VERSION ""

NS_ :

BS_:

BU_: ADAS CDM EBA EBAM HDMap HNS HUD VDC

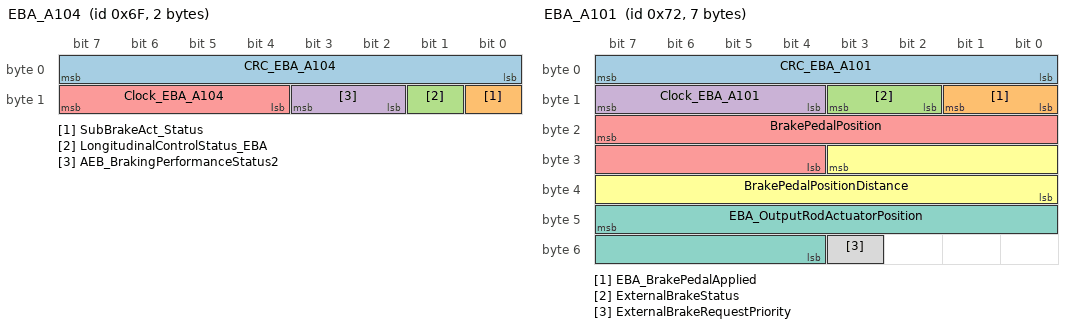
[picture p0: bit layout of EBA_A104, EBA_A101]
BO_ 111 EBA_A104: 2 EBA
  SG_ CRC_EBA_A104 : 7|8@0+ (1,0) [0|255] "" ADAS
  SG_ SubBrakeAct_Status : 8|1@0+ (1,0) [0|0] "" ADAS
  SG_ LongitudinalControlStatus_EBA : 9|1@0+ (1,0) [0|0] "" ADAS
  SG_ AEB_BrakingPerformanceStatus2 : 11|2@0+ (1,0) [0|0] "" ADAS
  SG_ Clock_EBA_A104 : 15|4@0+ (1,0) [0|15] "" ADAS

BO_ 114 EBA_A101: 7 EBA
  SG_ CRC_EBA_A101 : 7|8@0+ (1,0) [0|255] "" VDC
  SG_ EBA_BrakePedalApplied : 9|2@0+ (1,0) [0|0] "" VDC
  SG_ ExternalBrakeStatus : 11|2@0+ (1,0) [0|0] "" VDC
  SG_ Clock_EBA_A101 : 15|4@0+ (1,0) [0|15] "" VDC
  SG_ BrakePedalPosition : 23|12@0+ (0.03125,0) [0|100] "%" CDM
  SG_ BrakePedalPositionDistance : 27|12@0+ (0.015625,-5) [-5|47] "mm" CDM,VDC
  SG_ EBA_OutputRodActuatorPosition : 47|12@0+ (0.015625,-5) [-5|47] "mm" VDC
  SG_ ExternalBrakeRequestPriority : 51|1@0+ (1,0) [0|0] "" CDM,VDC

BO_ 116 ECM_A110: 8 CDM
  SG_ StopAutoPhase : 47|3@0+ (1,0) [0|0] "" HNS

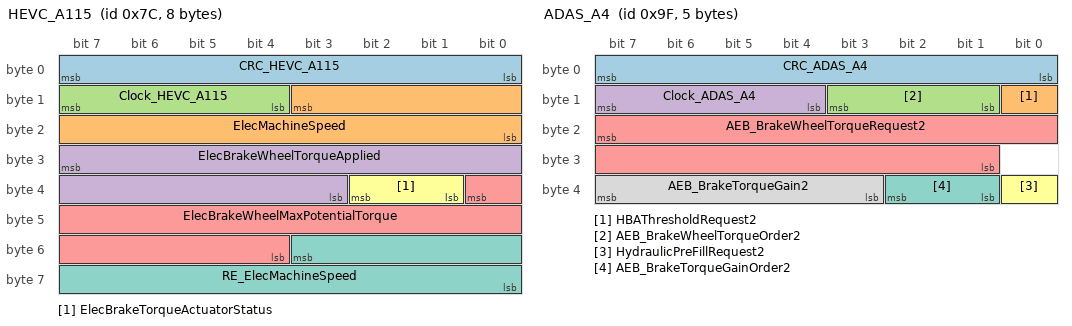
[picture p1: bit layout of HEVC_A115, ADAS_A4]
BO_ 124 HEVC_A115: 8 CDM
  SG_ CRC_HEVC_A115 : 7|8@0+ (1,0) [0|255] "" EBAM,VDC
  SG_ ElecMachineSpeed : 11|12@0+ (10,-20000) [-20000|20000] "rpm" EBAM,VDC
  SG_ Clock_HEVC_A115 : 15|4@0+ (1,0) [0|15] "" EBAM,VDC
  SG_ ElecBrakeWheelTorqueApplied : 31|13@0+ (1,0) [0|8190] "Nm" EBAM,VDC
  SG_ ElecBrakeWheelMaxPotentialTorque : 32|13@0+ (1,0) [0|8190] "Nm" EBAM,VDC
  SG_ ElecBrakeTorqueActuatorStatus : 34|2@0+ (1,0) [0|0] "" EBAM,VDC
  SG_ RE_ElecMachineSpeed : 51|12@0+ (10,-16390) [-16390|16390] "rpm" VDC

BO_ 159 ADAS_A4: 5 CDM
  SG_ CRC_ADAS_A4 : 7|8@0+ (1,0) [0|255] "" EBAM,VDC
  SG_ HBAThresholdRequest2 : 8|1@0+ (1,0) [0|0] "" EBAM,VDC
  SG_ AEB_BrakeWheelTorqueOrder2 : 11|3@0+ (1,0) [0|0] "" EBAM,VDC
  SG_ Clock_ADAS_A4 : 15|4@0+ (1,0) [0|15] "" EBAM,VDC
  SG_ AEB_BrakeWheelTorqueRequest2 : 23|15@0+ (1,0) [0|20000] "Nm" EBAM,VDC
  SG_ HydraulicPreFillRequest2 : 32|1@0+ (1,0) [0|0] "" EBAM,VDC
  SG_ AEB_BrakeTorqueGainOrder2 : 34|2@0+ (1,0) [0|0] "" EBAM,VDC
  SG_ AEB_BrakeTorqueGain2 : 39|5@0+ (0.05,1) [1|2] "" EBAM,VDC

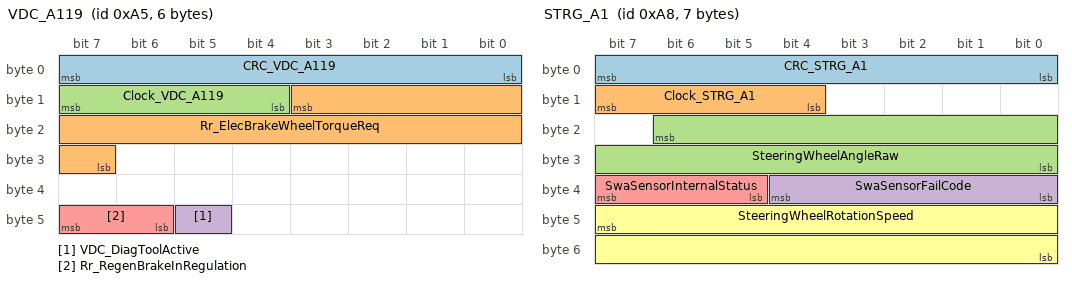
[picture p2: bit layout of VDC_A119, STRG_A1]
BO_ 165 VDC_A119: 6 VDC
  SG_ CRC_VDC_A119 : 7|8@0+ (1,0) [0|255] "" CDM,EBA
  SG_ Rr_ElecBrakeWheelTorqueReq : 11|13@0+ (1,0) [0|8190] "Nm" CDM
  SG_ Clock_VDC_A119 : 15|4@0+ (1,0) [0|15] "" CDM,EBA
  SG_ VDC_DiagToolActive : 45|1@0+ (1,0) [0|0] "" EBA
  SG_ Rr_RegenBrakeInRegulation : 47|2@0+ (1,0) [0|0] "" CDM

BO_ 168 STRG_A1: 7 CDM
  SG_ CRC_STRG_A1 : 7|8@0+ (1,0) [0|255] "" EBAM,VDC
  SG_ Clock_STRG_A1 : 15|4@0+ (1,0) [0|15] "" EBAM,VDC
  SG_ SteeringWheelAngleRaw : 22|15@0+ (0.1,-1080) [-1080|1080] "°" EBAM,VDC
  SG_ SwaSensorFailCode : 36|5@0+ (1,1) [1|31] "" EBAM,VDC
  SG_ SwaSensorInternalStatus : 39|3@0+ (1,0) [0|0] "" EBAM,VDC
  SG_ SteeringWheelRotationSpeed : 47|16@0+ (0.1,-3276.7) [-3276.7|3276.7] "°/s" EBAM,VDC

BO_ 336 AVM_A122: 7 CDM
  SG_ CRC_AVM_A122 : 7|8@0+ (1,0) [0|255] "" HNS,HUD
  SG_ Clock_AVM_A122 : 15|4@0+ (1,0) [0|15] "" HNS,HUD
  SG_ SubAD_ADmodeStatus : 52|3@0+ (1,0) [0|0] "" HNS,HUD

BO_ 354 VDC_A131: 5 VDC
  SG_ CRC_VDC_A131 : 7|8@0+ (1,0) [0|255] "" EBA
  SG_ Clock_VDC_A131 : 15|4@0+ (1,0) [0|15] "" EBA
  SG_ PathChangeRequest2 : 36|1@0+ (1,0) [0|0] "" EBA

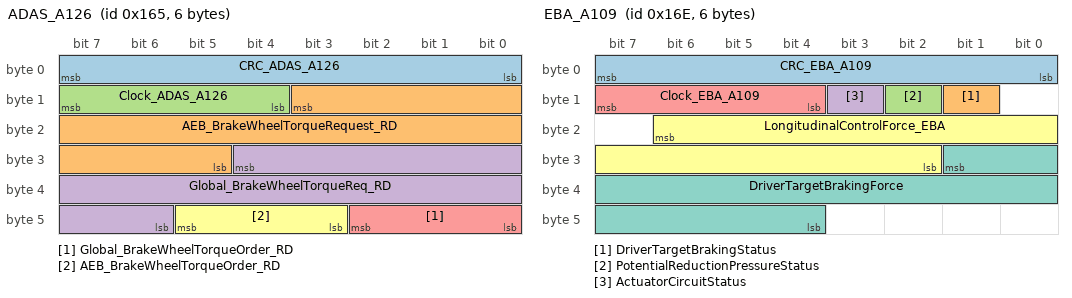
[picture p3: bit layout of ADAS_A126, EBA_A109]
BO_ 357 ADAS_A126: 6 ADAS
  SG_ CRC_ADAS_A126 : 7|8@0+ (1,0) [0|255] "" CDM,EBA
  SG_ AEB_BrakeWheelTorqueRequest_RD : 11|15@0+ (1,0) [0|20000] "Nm" EBA
  SG_ Clock_ADAS_A126 : 15|4@0+ (1,0) [0|15] "" CDM,EBA
  SG_ Global_BrakeWheelTorqueReq_RD : 28|15@0+ (1,0) [0|20000] "Nm" CDM,EBA
  SG_ Global_BrakeWheelTorqueOrder_RD : 42|3@0+ (1,0) [0|0] "" CDM,EBA
  SG_ AEB_BrakeWheelTorqueOrder_RD : 45|3@0+ (1,0) [0|0] "" EBA

BO_ 366 EBA_A109: 6 EBA
  SG_ CRC_EBA_A109 : 7|8@0+ (1,0) [0|255] "" VDC
  SG_ DriverTargetBrakingStatus : 9|1@0+ (1,0) [0|0] "" VDC
  SG_ PotentialReductionPressureStatus : 10|1@0+ (1,0) [0|0] "" VDC
  SG_ ActuatorCircuitStatus : 11|1@0+ (1,0) [0|0] "" VDC
  SG_ Clock_EBA_A109 : 15|4@0+ (1,0) [0|15] "" VDC
  SG_ LongitudinalControlForce_EBA : 22|13@0+ (8,0) [0|65000] "N" VDC
  SG_ DriverTargetBrakingForce : 25|14@0+ (8,0) [0|130000] "N" VDC

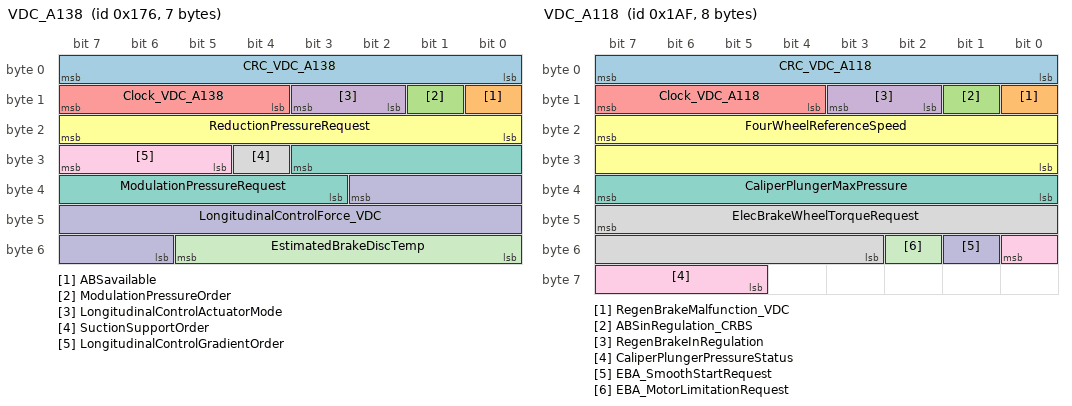
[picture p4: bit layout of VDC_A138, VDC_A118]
BO_ 374 VDC_A138: 7 VDC
  SG_ CRC_VDC_A138 : 7|8@0+ (1,0) [0|255] "" EBA
  SG_ ABSavailable : 8|1@0+ (1,0) [0|0] "" EBA
  SG_ ModulationPressureOrder : 9|1@0+ (1,0) [0|0] "" EBA
  SG_ LongitudinalControlActuatorMode : 11|2@0+ (1,0) [0|0] "" EBA
  SG_ Clock_VDC_A138 : 15|4@0+ (1,0) [0|15] "" EBA
  SG_ ReductionPressureRequest : 23|8@0+ (0.25,0) [0|60] "bar" EBA
  SG_ ModulationPressureRequest : 27|9@0+ (0.25,0) [0|120] "bar" EBA
  SG_ SuctionSupportOrder : 28|1@0+ (1,0) [0|0] "" EBA
  SG_ LongitudinalControlGradientOrder : 31|3@0+ (1,0) [0|0] "" EBA
  SG_ LongitudinalControlForce_VDC : 34|13@0+ (8,0) [0|65000] "N" EBA
  SG_ EstimatedBrakeDiscTemp : 53|6@0+ (15,0) [0|945] "?" EBA

BO_ 431 VDC_A118: 8 EBAM
  SG_ CRC_VDC_A118 : 7|8@0+ (1,0) [0|255] "" CDM,EBA
  SG_ RegenBrakeMalfunction_VDC : 8|1@0+ (1,0) [0|0] "" CDM
  SG_ ABSinRegulation_CRBS : 9|1@0+ (1,0) [0|0] "" EBA
  SG_ RegenBrakeInRegulation : 11|2@0+ (1,0) [0|0] "" CDM
  SG_ Clock_VDC_A118 : 15|4@0+ (1,0) [0|15] "" CDM,EBA
  SG_ FourWheelReferenceSpeed : 23|16@0+ (0.01,0) [0|655.34] "km/h" CDM,EBA
  SG_ CaliperPlungerMaxPressure : 39|8@0+ (0.1,0) [0|25] "MPa" EBA
  SG_ ElecBrakeWheelTorqueRequest : 47|13@0+ (1,0) [0|8190] "Nm" CDM
  SG_ CaliperPlungerPressureStatus : 48|4@0+ (1,0) [0|0] "" EBA
  SG_ EBA_SmoothStartRequest : 49|1@0+ (1,0) [0|0] "" EBA
  SG_ EBA_MotorLimitationRequest : 50|1@0+ (1,0) [0|0] "" EBA

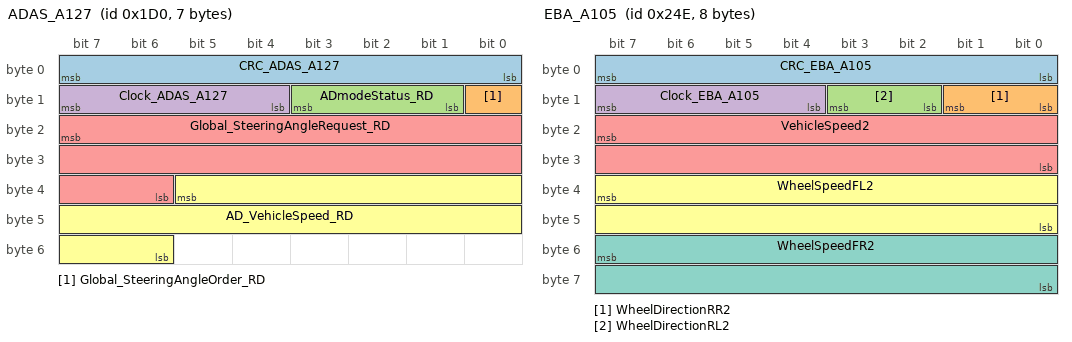
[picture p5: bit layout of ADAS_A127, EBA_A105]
BO_ 464 ADAS_A127: 7 ADAS
  SG_ CRC_ADAS_A127 : 7|8@0+ (1,0) [0|255] "" CDM,EBA,HNS,HUD,VDC
  SG_ Global_SteeringAngleOrder_RD : 8|1@0+ (1,0) [0|0] "" CDM
  SG_ ADmodeStatus_RD : 11|3@0+ (1,0) [0|0] "" EBA,HNS,HUD,VDC
  SG_ Clock_ADAS_A127 : 15|4@0+ (1,0) [0|15] "" CDM,EBA,HNS,HUD,VDC
  SG_ Global_SteeringAngleRequest_RD : 23|18@0+ (0.01,-1310) [-1310|1310] "deg" CDM
  SG_ AD_VehicleSpeed_RD : 37|16@0+ (0.01,0) [0|655.34] "km/h" EBA

BO_ 570 EBA_A108: 4 EBA
  SG_ CRC_EBA_A108 : 7|8@0+ (1,0) [0|255] "" ADAS
  SG_ VehicleSpeedBody2 : 11|16@0+ (0.01,0) [0|655.34] "km/h" ADAS
  SG_ Clock_EBA_A108 : 15|4@0+ (1,0) [0|15] "" ADAS

BO_ 590 EBA_A105: 8 EBA
  SG_ CRC_EBA_A105 : 7|8@0+ (1,0) [0|255] "" ADAS,CDM
  SG_ WheelDirectionRR2 : 9|2@0+ (1,0) [0|0] "" ADAS
  SG_ WheelDirectionRL2 : 11|2@0+ (1,0) [0|0] "" ADAS
  SG_ Clock_EBA_A105 : 15|4@0+ (1,0) [0|15] "" ADAS,CDM
  SG_ VehicleSpeed2 : 23|16@0+ (0.01,0) [0|655.34] "km/h" ADAS,CDM
  SG_ WheelSpeedFL2 : 39|16@0+ (0.0416666667,0) [0|2730.583333] "rpm" ADAS,CDM
  SG_ WheelSpeedFR2 : 55|16@0+ (0.0416666667,0) [0|2730.583333] "rpm" ADAS,CDM

BO_ 591 EBA_A106: 7 EBA
  SG_ CRC_EBA_A106 : 7|8@0+ (1,0) [0|255] "" ADAS,CDM
  SG_ Clock_EBA_A106 : 15|4@0+ (1,0) [0|15] "" ADAS,CDM
  SG_ WheelSpeedRL2 : 31|16@0+ (0.0416666667,0) [0|2730.583333] "rpm" ADAS,CDM
  SG_ WheelSpeedRR2 : 47|16@0+ (0.0416666667,0) [0|2730.583333] "rpm" ADAS,CDM

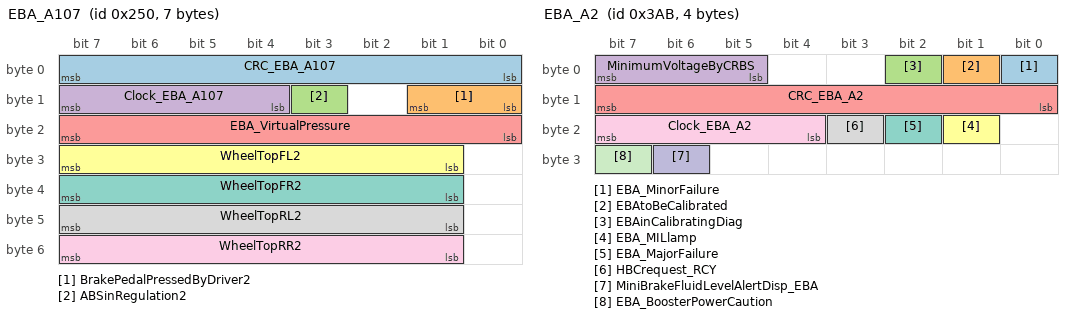
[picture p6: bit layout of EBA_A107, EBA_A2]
BO_ 592 EBA_A107: 7 EBA
  SG_ CRC_EBA_A107 : 7|8@0+ (1,0) [0|255] "" ADAS
  SG_ BrakePedalPressedByDriver2 : 9|2@0+ (1,0) [0|0] "" ADAS
  SG_ ABSinRegulation2 : 11|1@0+ (1,0) [0|0] "" ADAS
  SG_ Clock_EBA_A107 : 15|4@0+ (1,0) [0|15] "" ADAS
  SG_ EBA_VirtualPressure : 23|8@0+ (0.5,0) [0|126] "bar" ADAS
  SG_ WheelTopFL2 : 31|7@0+ (1,0) [0|96] "top" ADAS
  SG_ WheelTopFR2 : 39|7@0+ (1,0) [0|96] "top" ADAS
  SG_ WheelTopRL2 : 47|7@0+ (1,0) [0|96] "top" ADAS
  SG_ WheelTopRR2 : 55|7@0+ (1,0) [0|96] "top" ADAS

BO_ 650 VDC_A9: 8 VDC
  SG_ VehicleSpeed : 39|16@0+ (0.01,0) [0|655.34] "km/h" HDMap,HNS,HUD
  SG_ VehicleSpeedClock : 51|4@0+ (1,0) [0|15] "" HDMap
  SG_ VehicleSpeedCRC : 63|8@0+ (1,0) [0|255] "" HDMap

BO_ 732 EPKB_A102: 2 VDC
  SG_ CRC_EPKB_A102 : 7|8@0+ (1,0) [0|255] "" ADAS
  SG_ ParkingBrakeBindingStatus_RD : 11|2@0+ (1,0) [0|0] "" ADAS
  SG_ Clock_EPKB_A102 : 15|4@0+ (1,0) [0|15] "" ADAS

BO_ 747 EDL_A101: 2 CDM
  SG_ DiffLockOperatingFlag : 0|1@0+ (1,0) [0|0] "" EBAM,VDC
  SG_ DiffLockControllerFailure : 1|1@0+ (1,0) [0|0] "" EBAM,VDC
  SG_ DiffLockSwitching_EDL : 15|1@0+ (1,0) [0|0] "" VDC

BO_ 772 ADAS_A148: 4 ADAS
  SG_ AD_SteeringAngleDisplay : 31|8@0+ (1,0) [0|0] "" HUD

BO_ 806 USM_R3: 2 CDM
  SG_ FrontHeightBody : 7|8@0+ (1.5,-190.5) [-190.5|190.5] "mm" EBAM,VDC
  SG_ RearHeightBody : 15|8@0+ (1.5,-190.5) [-190.5|190.5] "mm" EBAM,VDC

BO_ 879 METER_A4: 4 CDM
  SG_ MemorizedDistanceTotalizer : 7|28@0+ (0.01,0) [0|2600000] "km" EBAM,VDC

BO_ 930 ADAS_A123: 6 CDM
  SG_ DMC_UnresponsiveAlertStatus : 37|3@0+ (1,0) [0|0] "" HUD

BO_ 939 EBA_A2: 4 EBA
  SG_ EBA_MinorFailure : 0|1@0+ (1,0) [0|0] "" CDM,VDC
  SG_ EBAtoBeCalibrated : 1|1@0+ (1,0) [0|0] "" CDM
  SG_ EBAinCalibratingDiag : 2|1@0+ (1,0) [0|0] "" CDM
  SG_ MinimumVoltageByCRBS : 7|3@0+ (0.5,12) [12|15] "V" CDM
  SG_ CRC_EBA_A2 : 15|8@0+ (1,0) [0|255] "" CDM,VDC
  SG_ EBA_MILlamp : 17|1@0+ (1,0) [0|0] "" CDM
  SG_ EBA_MajorFailure : 18|1@0+ (1,0) [0|0] "" CDM,VDC
  SG_ HBCrequest_RCY : 19|1@0+ (1,0) [0|0] "" VDC
  SG_ Clock_EBA_A2 : 23|4@0+ (1,0) [0|15] "" CDM,VDC
  SG_ MiniBrakeFluidLevelAlertDisp_EBA : 30|1@0+ (1,0) [0|0] "" VDC
  SG_ EBA_BoosterPowerCaution : 31|1@0+ (1,0) [0|0] "" CDM

BO_ 944 BCM_A117: 3 CDM
  SG_ CRC_BCM_A117 : 7|8@0+ (1,0) [0|255] "" EBA,EBAM,VDC
  SG_ Clock_BCM_A117 : 15|4@0+ (1,0) [0|15] "" EBA,EBAM,VDC
  SG_ RPES_Status : 23|3@0+ (1,0) [0|0] "" EBA,EBAM,VDC

BO_ 961 IVI_A112: 8 CDM
  SG_ DistanceBeforeNextAction : 7|40@0+ (1,0) [0|0] "" HUD
  SG_ UnitDistanceBeforeNextAction : 47|4@0+ (1,0) [0|0] "" HUD

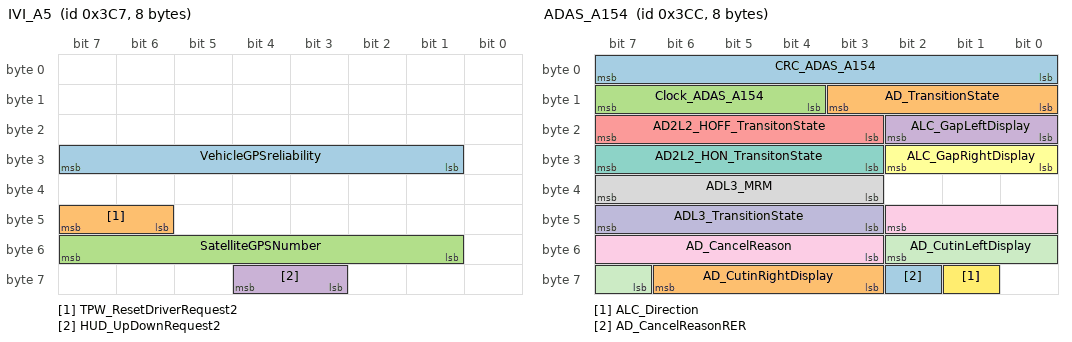
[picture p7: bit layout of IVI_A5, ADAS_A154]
BO_ 967 IVI_A5: 8 CDM
  SG_ VehicleGPSreliability : 31|7@0+ (1,0) [0|127] "" VDC
  SG_ TPW_ResetDriverRequest2 : 47|2@0+ (1,0) [0|0] "" EBAM,VDC
  SG_ SatelliteGPSNumber : 55|7@0+ (1,0) [0|126] "wu" VDC
  SG_ HUD_UpDownRequest2 : 60|2@0+ (1,0) [0|0] "" HUD

BO_ 972 ADAS_A154: 8 ADAS
  SG_ CRC_ADAS_A154 : 7|8@0+ (1,0) [0|255] "" HUD
  SG_ AD_TransitionState : 11|4@0+ (1,0) [0|0] "" HUD
  SG_ Clock_ADAS_A154 : 15|4@0+ (1,0) [0|15] "" HUD
  SG_ ALC_GapLeftDisplay : 18|3@0+ (1,0) [0|0] "" HUD
  SG_ AD2L2_HOFF_TransitonState : 23|5@0+ (1,0) [0|0] "" HUD
  SG_ ALC_GapRightDisplay : 26|3@0+ (1,0) [0|0] "" HUD
  SG_ AD2L2_HON_TransitonState : 31|5@0+ (1,0) [0|0] "" HUD
  SG_ ADL3_MRM : 39|5@0+ (1,0) [0|0] "" HUD
  SG_ AD_CancelReason : 42|8@0+ (1,0) [0|255] "CancelReason" HUD
  SG_ ADL3_TransitionState : 47|5@0+ (1,0) [0|0] "" HUD
  SG_ AD_CutinLeftDisplay : 50|4@0+ (1,0) [0|0] "" HUD
  SG_ ALC_Direction : 57|1@0+ (1,0) [0|0] "" HUD
  SG_ AD_CancelReasonRER : 58|1@0+ (1,0) [0|0] "" HUD
  SG_ AD_CutinRightDisplay : 62|4@0+ (1,0) [0|0] "" HUD

BO_ 974 ADAS_A147: 7 ADAS
  SG_ CRC_ADAS_A147 : 7|8@0+ (1,0) [0|255] "" VDC
  SG_ ParkingBrakeBindingRequest_RD : 11|1@0+ (1,0) [0|0] "" VDC
  SG_ Clock_ADAS_A147 : 15|4@0+ (1,0) [0|15] "" VDC

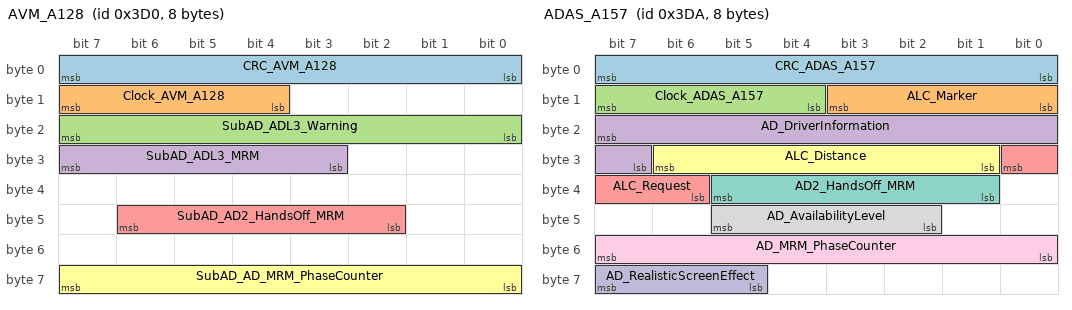
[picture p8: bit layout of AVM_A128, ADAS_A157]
BO_ 976 AVM_A128: 8 CDM
  SG_ CRC_AVM_A128 : 7|8@0+ (1,0) [0|255] "" HUD
  SG_ Clock_AVM_A128 : 15|4@0+ (1,0) [0|15] "" HUD
  SG_ SubAD_ADL3_Warning : 23|8@0+ (1,0) [0|255] "Warning" HUD
  SG_ SubAD_ADL3_MRM : 31|5@0+ (1,0) [0|0] "" HUD
  SG_ SubAD_AD2_HandsOff_MRM : 46|5@0+ (1,0) [0|0] "" HUD
  SG_ SubAD_AD_MRM_PhaseCounter : 63|8@0+ (0.2,-0.2) [0|50.6] "s" HUD

BO_ 977 CDM_A127: 3 CDM
  SG_ CRC_CDM_A127 : 7|8@0+ (1,0) [0|255] "" HNS
  SG_ HNS_Opening_Request : 8|1@0+ (1,0) [0|0] "" HNS
  SG_ HNS_Diagnostic_Req : 9|1@0+ (1,0) [0|0] "" HNS
  SG_ Clock_CDM_A127 : 15|4@0+ (1,0) [0|15] "" HNS

BO_ 986 ADAS_A157: 8 ADAS
  SG_ CRC_ADAS_A157 : 7|8@0+ (1,0) [0|255] "" HUD
  SG_ ALC_Marker : 11|4@0+ (1,0) [0|0] "" HUD
  SG_ Clock_ADAS_A157 : 15|4@0+ (1,0) [0|15] "" HUD
  SG_ AD_DriverInformation : 23|9@0+ (1,0) [0|511] "Instruction" HUD
  SG_ ALC_Request : 24|3@0+ (1,0) [0|0] "" HUD
  SG_ ALC_Distance : 30|6@0+ (100,-100) [0|6000] "m" HUD
  SG_ AD2_HandsOff_MRM : 37|5@0+ (1,0) [0|0] "" HUD
  SG_ AD_AvailabilityLevel : 45|4@0+ (1,0) [0|0] "" HUD
  SG_ AD_MRM_PhaseCounter : 55|8@0+ (0.2,-0.2) [0|50.6] "s" HUD
  SG_ AD_RealisticScreenEffect : 63|3@0+ (1,0) [0|0] "" HUD

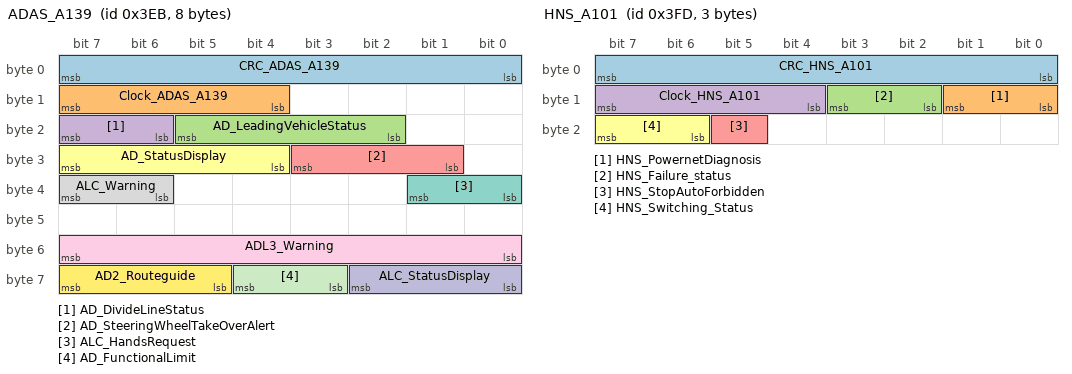
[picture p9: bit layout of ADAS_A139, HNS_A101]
BO_ 1003 ADAS_A139: 8 ADAS
  SG_ CRC_ADAS_A139 : 7|8@0+ (1,0) [0|255] "" HUD
  SG_ Clock_ADAS_A139 : 15|4@0+ (1,0) [0|15] "" HUD
  SG_ AD_LeadingVehicleStatus : 21|4@0+ (1,0) [0|0] "" HUD
  SG_ AD_DivideLineStatus : 23|2@0+ (1,0) [0|0] "" HUD
  SG_ AD_SteeringWheelTakeOverAlert : 27|3@0+ (1,0) [0|0] "" HUD
  SG_ AD_StatusDisplay : 31|4@0+ (1,0) [0|0] "" HUD
  SG_ ALC_HandsRequest : 33|2@0+ (1,0) [0|0] "" HUD
  SG_ ALC_Warning : 39|2@0+ (1,0) [0|0] "" HUD
  SG_ ADL3_Warning : 55|8@0+ (1,0) [0|255] "Warning" HUD
  SG_ ALC_StatusDisplay : 58|3@0+ (1,0) [0|0] "" HUD
  SG_ AD_FunctionalLimit : 60|2@0+ (1,0) [0|0] "" HUD
  SG_ AD2_Routeguide : 63|3@0+ (1,0) [0|0] "" HUD

BO_ 1021 HNS_A101: 3 HNS
  SG_ CRC_HNS_A101 : 7|8@0+ (1,0) [0|255] "" CDM
  SG_ HNS_PowernetDiagnosis : 9|2@0+ (1,0) [0|0] "" CDM
  SG_ HNS_Failure_status : 11|2@0+ (1,0) [0|0] "" CDM
  SG_ Clock_HNS_A101 : 15|4@0+ (1,0) [0|15] "" CDM
  SG_ HNS_StopAutoForbidden : 21|1@0+ (1,0) [0|0] "" CDM
  SG_ HNS_Switching_Status : 23|2@0+ (1,0) [0|0] "" CDM

BO_ 1058 FRCAMERA_A111: 5 CDM
  SG_ TSR_ConfidenceLevel : 39|3@0+ (20,0) [0|100] "%" HUD

BO_ 1068 HEVC_A108: 8 CDM
  SG_ AnticipatedElectricGearChange : 0|1@0+ (1,0) [0|0] "" VDC
  SG_ VehicleTractionMode : 15|3@0+ (1,0) [0|0] "" EBAM,VDC

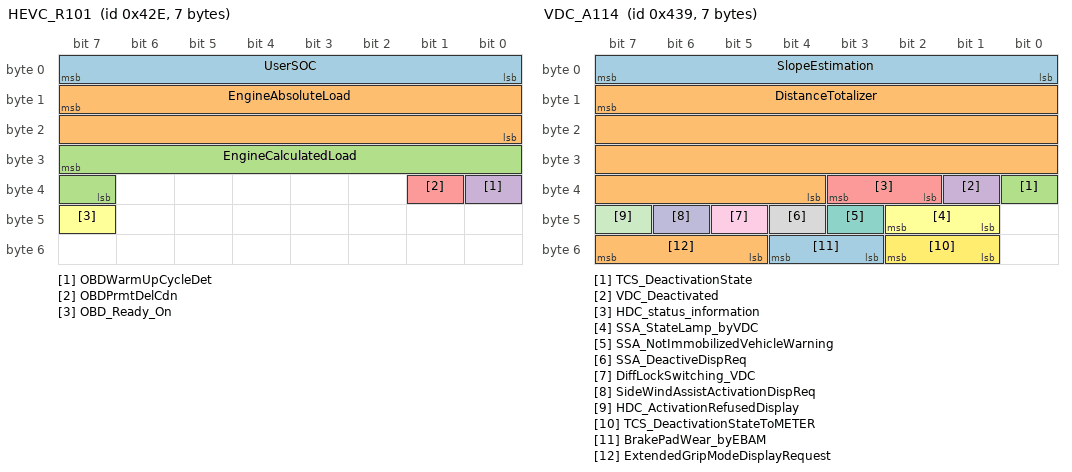
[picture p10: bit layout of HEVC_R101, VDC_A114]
BO_ 1070 HEVC_R101: 7 CDM
  SG_ UserSOC : 7|8@0+ (0.392157,0) [0|100] "%" EBA,EBAM
  SG_ EngineAbsoluteLoad : 15|16@0+ (0.39,0) [0|25700] "%" EBA
  SG_ EngineCalculatedLoad : 31|9@0+ (0.39,0) [0|100] "%" EBA,EBAM,VDC
  SG_ OBDWarmUpCycleDet : 32|1@0+ (1,0) [0|0] "" EBA,EBAM,VDC
  SG_ OBDPrmtDelCdn : 33|1@0+ (1,0) [0|0] "" EBA,EBAM,VDC
  SG_ OBD_Ready_On : 47|1@0+ (1,0) [0|0] "" EBA,EBAM,VDC

BO_ 1081 VDC_A114: 7 EBAM
  SG_ SlopeEstimation : 7|8@0+ (0.2,-15) [-15|15] "°" CDM
  SG_ DistanceTotalizer : 15|28@0+ (0.01,0) [0|2600000] "km" CDM,EBA,HNS,HUD
  SG_ TCS_DeactivationState : 32|1@0+ (1,0) [0|0] "" CDM
  SG_ VDC_Deactivated : 33|1@0+ (1,0) [0|0] "" CDM
  SG_ HDC_status_information : 35|2@0+ (1,0) [0|0] "" CDM
  SG_ SSA_StateLamp_byVDC : 42|2@0+ (1,0) [0|0] "" CDM
  SG_ SSA_NotImmobilizedVehicleWarning : 43|1@0+ (1,0) [0|0] "" CDM
  SG_ SSA_DeactiveDispReq : 44|1@0+ (1,0) [0|0] "" CDM
  SG_ DiffLockSwitching_VDC : 45|1@0+ (1,0) [0|0] "" CDM
  SG_ SideWindAssistActivationDispReq : 46|1@0+ (1,0) [0|0] "" CDM
  SG_ HDC_ActivationRefusedDisplay : 47|1@0+ (1,0) [0|0] "" CDM
  SG_ TCS_DeactivationStateToMETER : 50|2@0+ (1,0) [0|0] "" CDM
  SG_ BrakePadWear_byEBAM : 52|2@0+ (1,0) [0|0] "" CDM
  SG_ ExtendedGripModeDisplayRequest : 55|3@0+ (1,0) [0|0] "" CDM

BO_ 1099 ATCU_A109: 8 CDM
  SG_ AT_GearShiftRefused : 31|1@0+ (1,0) [0|0] "" HUD
  SG_ ATCVT_RangeIndicationExtended : 44|6@0+ (1,0) [0|0] "" HUD

BO_ 1101 BCM_A107: 5 ADAS
  SG_ FlashingIndicatorStatusDisplay : 23|3@0+ (1,0) [0|0] "" HUD

BO_ 1104 METER_A103: 8 CDM
  SG_ RawFuelGaugeResistance : 7|10@0+ (1,0) [0|1022] "Ohm" EBA

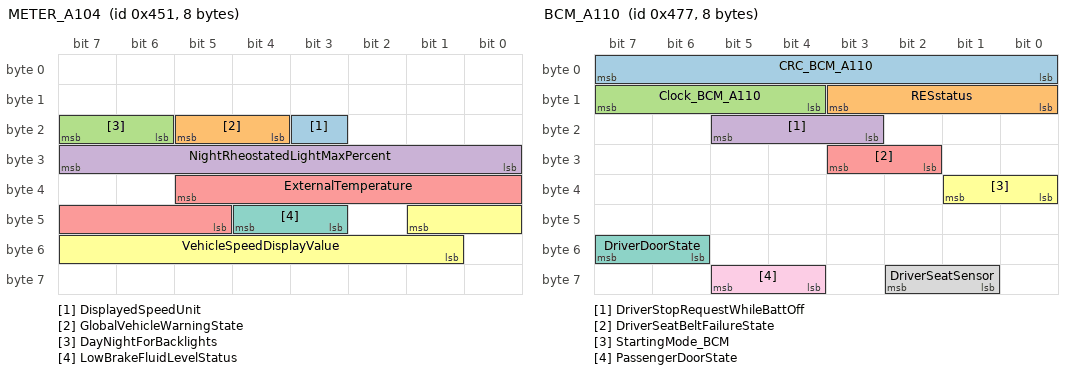
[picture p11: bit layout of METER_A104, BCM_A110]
BO_ 1105 METER_A104: 8 CDM
  SG_ DisplayedSpeedUnit : 19|1@0+ (1,0) [0|0] "" HUD
  SG_ GlobalVehicleWarningState : 21|2@0+ (1,0) [0|0] "" HUD
  SG_ DayNightForBacklights : 23|2@0+ (1,0) [0|0] "" HUD
  SG_ NightRheostatedLightMaxPercent : 31|8@0+ (0.4,0) [0|100] "%" HUD
  SG_ ExternalTemperature : 37|9@0+ (0.25,-50) [-50|70] "°C" HUD
  SG_ VehicleSpeedDisplayValue : 41|9@0+ (1,0) [0|510] "" HUD
  SG_ LowBrakeFluidLevelStatus : 44|2@0+ (1,0) [0|0] "" EBA

BO_ 1107 USM_A101: 8 CDM
  SG_ CRC_USM_A101 : 7|8@0+ (1,0) [0|255] "" EBA
  SG_ Clock_USM_A101 : 15|4@0+ (1,0) [0|15] "" EBA
  SG_ IgnitionSupplyConfirmation : 20|1@0+ (1,0) [0|0] "" EBA,HUD
  SG_ BatteryVoltage : 31|8@0+ (0.06,6) [6|18] "V" EBA,HNS,HUD

BO_ 1108 USM_A103: 8 CDM
  SG_ SOCBattery14V : 13|6@0+ (0.5,69) [69|100] "%" HNS
  SG_ Storage12V_SwitchRequest : 53|1@0+ (1,0) [0|0] "" HNS

BO_ 1110 BMS12V_A101: 8 CDM
  SG_ BMS12V_StorageSOC : 37|10@0+ (0.1,0) [0|100] "%" HNS
  SG_ BMS12V_SwitchState : 41|1@0+ (1,0) [0|0] "" HNS
  SG_ BMS12V_StorageFailure : 43|2@0+ (1,0) [0|0] "" HNS

BO_ 1116 CDM_A116: 8 CDM
  SG_ SSA_StateLamp : 3|2@0+ (1,0) [0|0] "" HUD

BO_ 1119 ECM_A108: 4 CDM
  SG_ EngineCoolantTemp : 23|8@0+ (1,-40) [-40|214] "°C" EBA

BO_ 1137 ECM_A114: 8 CDM
  SG_ RequestedSpeedDisplayRequest : 15|8@0+ (1,0) [0|253] "" HUD
  SG_ Maintenance_Mode_Status : 25|2@0+ (1,0) [0|0] "" EBA,EBAM,VDC
  SG_ CruiseControlStatus : 31|3@0+ (1,0) [0|0] "" EBAM,HUD,VDC

BO_ 1138 ECM_A116: 8 CDM
  SG_ OverspeedIndicationDisplayReq : 25|1@0+ (1,0) [0|0] "" HUD
  SG_ OverSpeedAlert_SL : 47|1@0+ (1,0) [0|0] "" HUD

BO_ 1139 ECM_A117: 6 CDM
  SG_ AtmoPressure : 7|10@0+ (0.1,10) [10|110] "kPa" VDC
  SG_ Rr_TransmRangeEngaged_Current : 26|2@0+ (1,0) [0|0] "" VDC
  SG_ AcceleratorPedalPositionD : 39|8@0+ (0.39215686274509803,0) [0|100] "%" EBA,EBAM,VDC
  SG_ Rr_TransmRangeEngaged_Target : 47|2@0+ (1,0) [0|0] "" VDC

BO_ 1140 ADAS_A116: 8 CDM
  SG_ LKA_AlertStatus : 9|2@0+ (1,0) [0|0] "" HUD
  SG_ LKA_SWheelTakeOverAlert_v3 : 23|3@0+ (1,0) [0|0] "" HUD

BO_ 1143 BCM_A110: 8 CDM
  SG_ CRC_BCM_A110 : 7|8@0+ (1,0) [0|255] "" EBAM,VDC
  SG_ RESstatus : 11|4@0+ (1,0) [0|0] "" HUD
  SG_ Clock_BCM_A110 : 15|4@0+ (1,0) [0|15] "" EBAM,VDC
  SG_ DriverStopRequestWhileBattOff : 21|3@0+ (1,0) [0|0] "" EBAM,VDC
  SG_ DriverSeatBeltFailureState : 27|2@0+ (1,0) [0|0] "" EBAM,VDC
  SG_ StartingMode_BCM : 33|2@0+ (1,0) [0|0] "" EBAM,VDC
  SG_ DriverDoorState : 55|2@0+ (1,0) [0|0] "" EBAM,VDC
  SG_ DriverSeatSensor : 58|2@0+ (1,0) [0|0] "" EBAM
  SG_ PassengerDoorState : 61|2@0+ (1,0) [0|0] "" EBAM,VDC

BO_ 1145 BCM_A112: 8 CDM
  SG_ ProbableCustomerFeedBackNeed : 41|1@0+ (1,0) [0|0] "" EBAM,VDC
  SG_ AutoACC2Status_MM : 55|2@0+ (1,0) [0|0] "" HUD

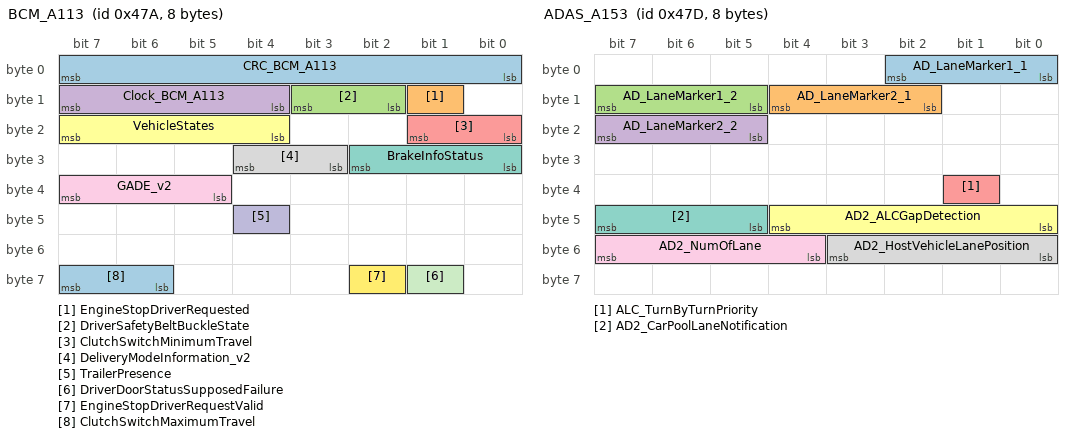
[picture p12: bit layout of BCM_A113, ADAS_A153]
BO_ 1146 BCM_A113: 8 CDM
  SG_ CRC_BCM_A113 : 7|8@0+ (1,0) [0|255] "" EBAM,VDC
  SG_ EngineStopDriverRequested : 9|1@0+ (1,0) [0|0] "" EBAM,VDC
  SG_ DriverSafetyBeltBuckleState : 11|2@0+ (1,0) [0|0] "" EBAM,VDC
  SG_ Clock_BCM_A113 : 15|4@0+ (1,0) [0|15] "" EBAM,VDC
  SG_ ClutchSwitchMinimumTravel : 17|2@0+ (1,0) [0|0] "" EBAM,VDC
  SG_ VehicleStates : 23|4@0+ (1,0) [0|0] "" EBAM,HDMap,HNS,HUD,VDC
  SG_ BrakeInfoStatus : 26|3@0+ (1,0) [0|0] "" EBAM,VDC
  SG_ DeliveryModeInformation_v2 : 28|2@0+ (1,0) [0|0] "" EBAM,HUD,VDC
  SG_ GADE_v2 : 39|3@0+ (1,0) [0|0] "" EBAM,HNS,HUD,VDC
  SG_ TrailerPresence : 44|1@0+ (1,0) [0|0] "" EBAM,VDC
  SG_ DriverDoorStatusSupposedFailure : 57|1@0+ (1,0) [0|0] "" EBAM,VDC
  SG_ EngineStopDriverRequestValid : 58|1@0+ (1,0) [0|0] "" EBAM,VDC
  SG_ ClutchSwitchMaximumTravel : 63|2@0+ (1,0) [0|0] "" EBAM,VDC

BO_ 1149 ADAS_A153: 8 ADAS
  SG_ AD_LaneMarker1_1 : 2|3@0+ (1,0) [0|0] "" HUD
  SG_ AD_LaneMarker2_1 : 12|3@0+ (1,0) [0|0] "" HUD
  SG_ AD_LaneMarker1_2 : 15|3@0+ (1,0) [0|0] "" HUD
  SG_ AD_LaneMarker2_2 : 23|3@0+ (1,0) [0|0] "" HUD
  SG_ ALC_TurnByTurnPriority : 33|1@0+ (1,0) [0|0] "" HUD
  SG_ AD2_ALCGapDetection : 44|5@0+ (1,0) [0|0] "" HUD
  SG_ AD2_CarPoolLaneNotification : 47|3@0+ (1,0) [0|0] "" HUD
  SG_ AD2_HostVehicleLanePosition : 51|4@0+ (1,0) [0|0] "" HUD
  SG_ AD2_NumOfLane : 55|4@0+ (1,0) [0|0] "" HUD

BO_ 1176 ADAS_N104: 8 CDM
  SG_ RMF_StatusDisplay : 51|3@0+ (1,0) [0|0] "" HUD
  SG_ RMF_StateDisplayRequest : 55|4@0+ (1,0) [0|0] "" HUD
  SG_ RMF_FailureDisplay : 63|3@0+ (1,0) [0|0] "" HUD

BO_ 1189 BCM_N101: 8 CDM
  SG_ UserIdentification_IKeyLink_v2 : 39|4@0+ (1,0) [0|0] "" HUD

BO_ 1203 FRCAMERA_A110: 5 CDM
  SG_ OSPSpeedLimit_Display : 7|8@0+ (1,5) [5|200] "Kmh/Mph" HUD

BO_ 1278 FrCamADAS_R101: 5 CDM
  SG_ LCA_WarningStatus : 26|3@0+ (1,0) [0|0] "" HUD

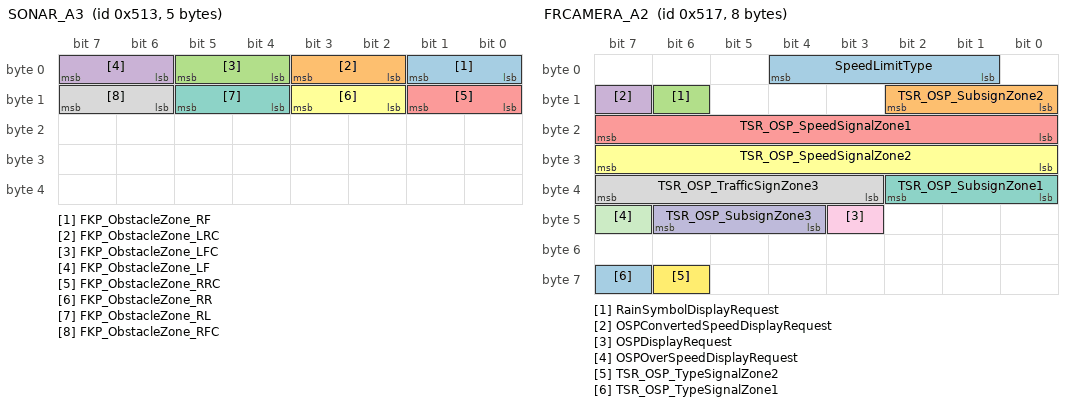
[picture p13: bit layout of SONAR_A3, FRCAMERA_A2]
BO_ 1299 SONAR_A3: 5 CDM
  SG_ FKP_ObstacleZone_RF : 1|2@0+ (1,0) [0|0] "" HUD
  SG_ FKP_ObstacleZone_LRC : 3|2@0+ (1,0) [0|0] "" HUD
  SG_ FKP_ObstacleZone_LFC : 5|2@0+ (1,0) [0|0] "" HUD
  SG_ FKP_ObstacleZone_LF : 7|2@0+ (1,0) [0|0] "" HUD
  SG_ FKP_ObstacleZone_RRC : 9|2@0+ (1,0) [0|0] "" HUD
  SG_ FKP_ObstacleZone_RR : 11|2@0+ (1,0) [0|0] "" HUD
  SG_ FKP_ObstacleZone_RL : 13|2@0+ (1,0) [0|0] "" HUD
  SG_ FKP_ObstacleZone_RFC : 15|2@0+ (1,0) [0|0] "" HUD

BO_ 1303 FRCAMERA_A2: 8 CDM
  SG_ SpeedLimitType : 4|4@0+ (1,0) [0|0] "" HUD
  SG_ TSR_OSP_SubsignZone2 : 10|3@0+ (1,0) [0|0] "" HUD
  SG_ RainSymbolDisplayRequest : 14|1@0+ (1,0) [0|0] "" HUD
  SG_ OSPConvertedSpeedDisplayRequest : 15|1@0+ (1,0) [0|0] "" HUD
  SG_ TSR_OSP_SpeedSignalZone1 : 23|8@0+ (1,0) [0|200] "wu" HUD
  SG_ TSR_OSP_SpeedSignalZone2 : 31|8@0+ (1,0) [0|200] "wu" HUD
  SG_ TSR_OSP_SubsignZone1 : 34|3@0+ (1,0) [0|0] "" HUD
  SG_ TSR_OSP_TrafficSignZone3 : 39|5@0+ (1,0) [0|0] "" HUD
  SG_ OSPDisplayRequest : 43|1@0+ (1,0) [0|0] "" HUD
  SG_ TSR_OSP_SubsignZone3 : 46|3@0+ (1,0) [0|0] "" HUD
  SG_ OSPOverSpeedDisplayRequest : 47|1@0+ (1,0) [0|0] "" HUD
  SG_ TSR_OSP_TypeSignalZone2 : 62|1@0+ (1,0) [0|0] "" HUD
  SG_ TSR_OSP_TypeSignalZone1 : 63|1@0+ (1,0) [0|0] "" HUD

BO_ 1315 BCM_A8: 3 CDM
  SG_ AbsoluteTimeSince1rstIgnition : 7|24@0+ (1,0) [0|1.677E7] "min" EBAM,VDC

BO_ 1318 IVI_A3: 6 CDM
  SG_ VehicleSpeedbyGPS : 23|14@0+ (0.03,0) [0|255] "km/h" VDC

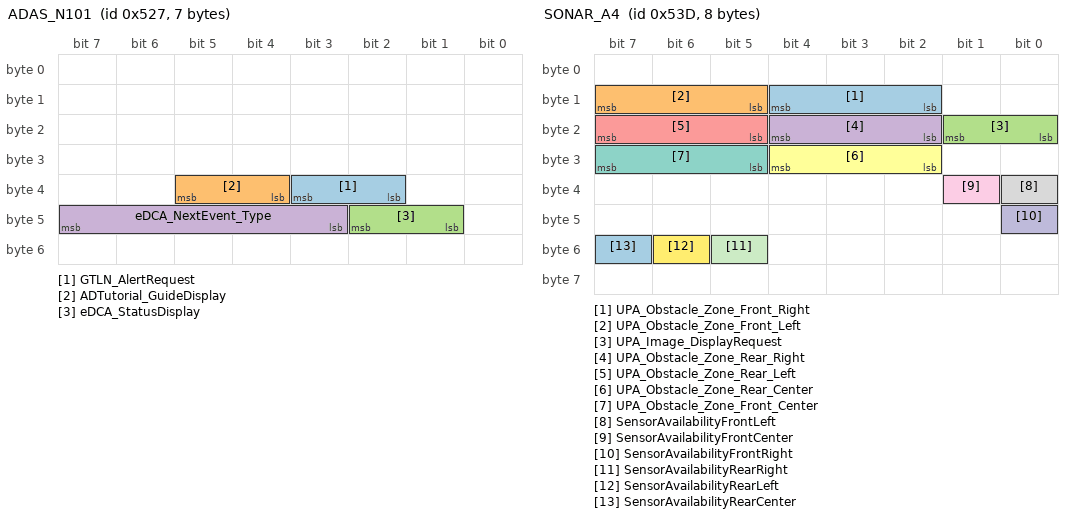
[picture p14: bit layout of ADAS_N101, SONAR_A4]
BO_ 1319 ADAS_N101: 7 CDM
  SG_ GTLN_AlertRequest : 35|2@0+ (1,0) [0|0] "" HUD
  SG_ ADTutorial_GuideDisplay : 37|2@0+ (1,0) [0|0] "" HUD
  SG_ eDCA_StatusDisplay : 42|2@0+ (1,0) [0|0] "" HUD
  SG_ eDCA_NextEvent_Type : 47|5@0+ (1,0) [0|0] "" HUD

BO_ 1341 SONAR_A4: 8 CDM
  SG_ UPA_Obstacle_Zone_Front_Right : 12|3@0+ (1,0) [0|0] "" HUD
  SG_ UPA_Obstacle_Zone_Front_Left : 15|3@0+ (1,0) [0|0] "" HUD
  SG_ UPA_Image_DisplayRequest : 17|2@0+ (1,0) [0|0] "" HUD
  SG_ UPA_Obstacle_Zone_Rear_Right : 20|3@0+ (1,0) [0|0] "" HUD
  SG_ UPA_Obstacle_Zone_Rear_Left : 23|3@0+ (1,0) [0|0] "" HUD
  SG_ UPA_Obstacle_Zone_Rear_Center : 28|3@0+ (1,0) [0|0] "" HUD
  SG_ UPA_Obstacle_Zone_Front_Center : 31|3@0+ (1,0) [0|0] "" HUD
  SG_ SensorAvailabilityFrontLeft : 32|1@0+ (1,0) [0|0] "" HUD
  SG_ SensorAvailabilityFrontCenter : 33|1@0+ (1,0) [0|0] "" HUD
  SG_ SensorAvailabilityFrontRight : 40|1@0+ (1,0) [0|0] "" HUD
  SG_ SensorAvailabilityRearRight : 53|1@0+ (1,0) [0|0] "" HUD
  SG_ SensorAvailabilityRearLeft : 54|1@0+ (1,0) [0|0] "" HUD
  SG_ SensorAvailabilityRearCenter : 55|1@0+ (1,0) [0|0] "" HUD

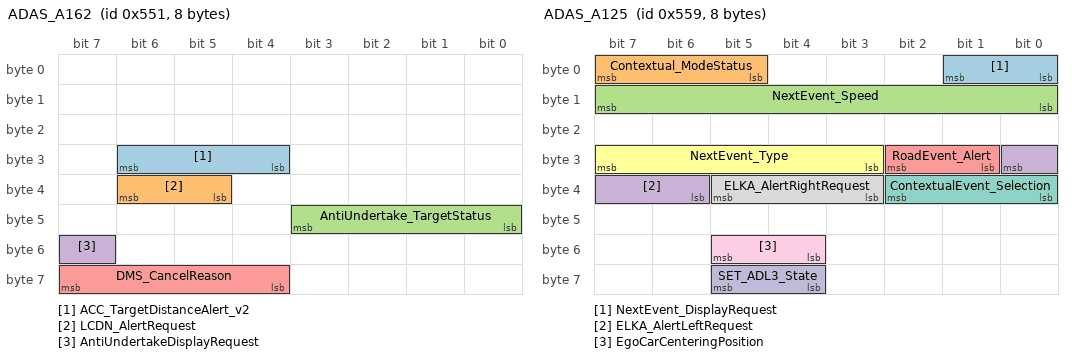
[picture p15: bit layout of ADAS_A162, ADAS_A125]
BO_ 1361 ADAS_A162: 8 CDM
  SG_ ACC_TargetDistanceAlert_v2 : 30|3@0+ (1,0) [0|0] "" HUD
  SG_ LCDN_AlertRequest : 38|2@0+ (1,0) [0|0] "" HUD
  SG_ AntiUndertake_TargetStatus : 43|4@0+ (1,0) [0|0] "" HUD
  SG_ AntiUndertakeDisplayRequest : 55|1@0+ (1,0) [0|0] "" HUD
  SG_ DMS_CancelReason : 63|4@0+ (1,0) [0|0] "" HUD

BO_ 1369 ADAS_A125: 8 CDM
  SG_ NextEvent_DisplayRequest : 1|2@0+ (1,0) [0|0] "" HUD
  SG_ Contextual_ModeStatus : 7|3@0+ (1,0) [0|0] "" HUD
  SG_ NextEvent_Speed : 15|8@0+ (1,0) [0|200] "wu" HUD
  SG_ ELKA_AlertLeftRequest : 24|3@0+ (1,0) [0|0] "" HUD
  SG_ RoadEvent_Alert : 26|2@0+ (1,0) [0|0] "" HUD
  SG_ NextEvent_Type : 31|5@0+ (1,0) [0|0] "" HUD
  SG_ ContextualEvent_Selection : 34|3@0+ (1,0) [0|0] "" HUD
  SG_ ELKA_AlertRightRequest : 37|3@0+ (1,0) [0|0] "" HUD
  SG_ EgoCarCenteringPosition : 53|2@0+ (1,0) [0|0] "" HUD
  SG_ SET_ADL3_State : 61|2@0+ (1,0) [0|0] "" HUD

BO_ 1371 HUD_A103: 2 HUD
  SG_ CRC_HUD_A103 : 7|8@0+ (1,0) [0|255] "" ADAS,CDM
  SG_ HUD_CAN_CorruptionDetection : 11|2@0+ (1,0) [0|0] "" ADAS,CDM
  SG_ Clock_HUD_A103 : 15|4@0+ (1,0) [0|15] "" ADAS,CDM

BO_ 1380 METER_A106: 8 CDM
  SG_ MeterLanguageStatus : 23|8@0+ (1,0) [0|0] "" HUD

BO_ 1381 SRRR_A106: 6 CDM
  SG_ BSWrad_StatusDisplay_v2 : 39|3@0+ (1,0) [0|0] "" HUD

BO_ 1384 IVI_A123: 8 CDM
  SG_ CurrentSpecificUserState : 11|2@0+ (1,0) [0|0] "" EBAM,VDC

BO_ 1388 HUD_A102: 2 HUD
  SG_ CRC_HUD_A102 : 7|8@0+ (1,0) [0|255] "" ADAS
  SG_ HUD_Status : 11|2@0+ (1,0) [0|0] "" ADAS
  SG_ Clock_HUD_A102 : 15|4@0+ (1,0) [0|15] "" ADAS

BO_ 1392 IVI_A119: 8 CDM
  SG_ HUD_ADASactivationRequest2 : 1|2@0+ (1,0) [0|0] "" HUD
  SG_ HUD_TurnByTurnActivationRequest2 : 13|2@0+ (1,0) [0|0] "" HUD
  SG_ HUD_TSRactivationRequest2 : 15|2@0+ (1,0) [0|0] "" HUD

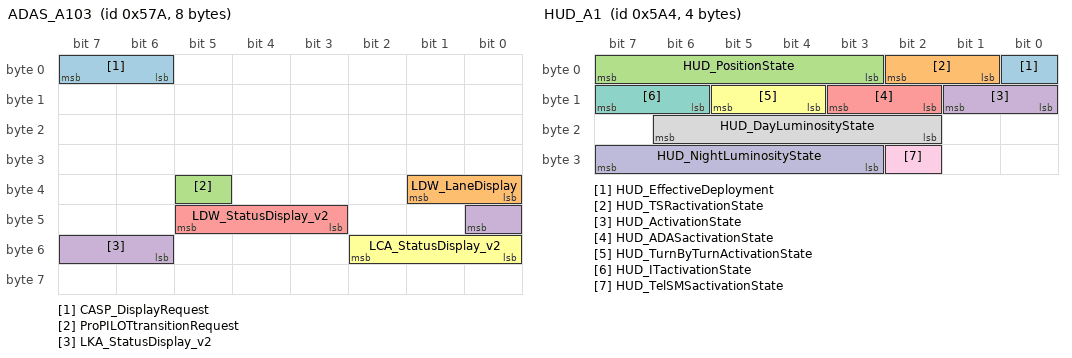
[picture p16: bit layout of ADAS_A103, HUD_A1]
BO_ 1402 ADAS_A103: 8 CDM
  SG_ CASP_DisplayRequest : 7|2@0+ (1,0) [0|0] "" HUD
  SG_ LDW_LaneDisplay : 33|2@0+ (1,0) [0|0] "" HUD
  SG_ ProPILOTtransitionRequest : 37|1@0+ (1,0) [0|0] "" HUD
  SG_ LKA_StatusDisplay_v2 : 40|3@0+ (1,0) [0|0] "" HUD
  SG_ LDW_StatusDisplay_v2 : 45|3@0+ (1,0) [0|0] "" HUD
  SG_ LCA_StatusDisplay_v2 : 50|3@0+ (1,0) [0|0] "" HUD

BO_ 1414 VDC_A136: 2 VDC
  SG_ CRC_VDC_A136 : 7|8@0+ (1,0) [0|255] "" EBA
  SG_ BrakeMapChangeRequest : 11|3@0+ (1,0) [0|0] "" EBA
  SG_ Clock_VDC_A136 : 15|4@0+ (1,0) [0|15] "" EBA

BO_ 1444 HUD_A1: 4 HUD
  SG_ HUD_EffectiveDeployment : 0|1@0+ (1,0) [0|0] "" CDM
  SG_ HUD_TSRactivationState : 2|2@0+ (1,0) [0|0] "" CDM
  SG_ HUD_PositionState : 7|5@0+ (1,0) [0|0] "" CDM
  SG_ HUD_ActivationState : 9|2@0+ (1,0) [0|0] "" CDM
  SG_ HUD_ADASactivationState : 11|2@0+ (1,0) [0|0] "" CDM
  SG_ HUD_TurnByTurnActivationState : 13|2@0+ (1,0) [0|0] "" CDM
  SG_ HUD_ITactivationState : 15|2@0+ (1,0) [0|0] "" CDM
  SG_ HUD_DayLuminosityState : 22|5@0+ (1,0) [0|0] "" CDM
  SG_ HUD_TelSMSactivationState : 26|1@0+ (1,0) [0|0] "" CDM
  SG_ HUD_NightLuminosityState : 31|5@0+ (1,0) [0|0] "" CDM

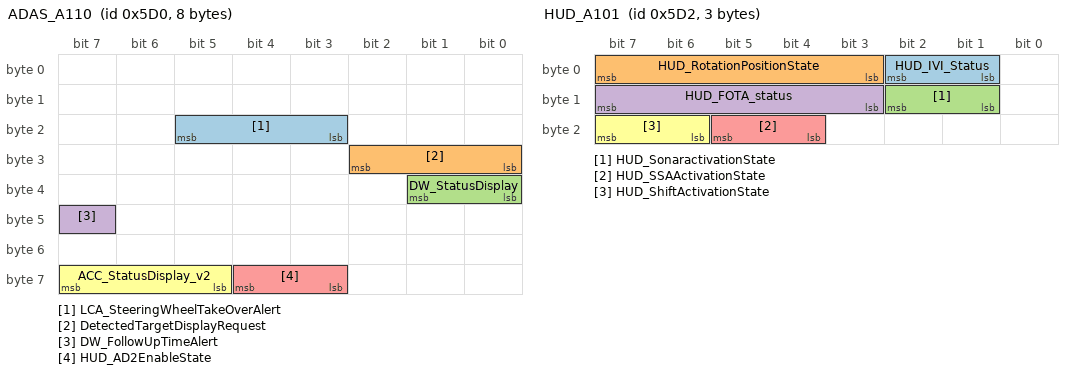
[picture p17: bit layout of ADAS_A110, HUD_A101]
BO_ 1488 ADAS_A110: 8 CDM
  SG_ LCA_SteeringWheelTakeOverAlert : 21|3@0+ (1,0) [0|0] "" HUD
  SG_ DetectedTargetDisplayRequest : 26|3@0+ (1,0) [0|0] "" HUD
  SG_ DW_StatusDisplay : 33|2@0+ (1,0) [0|0] "" HUD
  SG_ DW_FollowUpTimeAlert : 47|1@0+ (1,0) [0|0] "" HUD
  SG_ HUD_AD2EnableState : 60|2@0+ (1,0) [0|0] "" HUD
  SG_ ACC_StatusDisplay_v2 : 63|3@0+ (1,0) [0|0] "" HUD

BO_ 1490 HUD_A101: 3 HUD
  SG_ HUD_IVI_Status : 2|2@0+ (1,0) [0|0] "" CDM
  SG_ HUD_RotationPositionState : 7|5@0+ (1,0) [0|0] "" CDM
  SG_ HUD_SonaractivationState : 10|2@0+ (1,0) [0|0] "" CDM
  SG_ HUD_FOTA_status : 15|5@0+ (1,0) [0|0] "" CDM
  SG_ HUD_SSAActivationState : 21|2@0+ (1,0) [0|0] "" CDM
  SG_ HUD_ShiftActivationState : 23|2@0+ (1,0) [0|0] "" CDM

BO_ 1498 ADAS_A155: 5 ADAS
  SG_ AD_DistanceDuration : 7|14@0+ (0.1,-0.1) [0|1638] "km" HUD
  SG_ AD_TimeDuration : 9|10@0+ (1,-1) [0|1022] "min" HUD

BO_ 1501 FRCAMERA_A109: 5 CDM
  SG_ TSR_OSP_SubsignAdditional_Zone3 : 9|2@0+ (1,0) [0|0] "" HUD
  SG_ TSR_OSP_SubsignAdditional_Zone2 : 11|2@0+ (1,0) [0|0] "" HUD
  SG_ TSR_OSP_SubsignAdditional_Zone1 : 13|2@0+ (1,0) [0|0] "" HUD

BO_ 1506 BCM_A101: 8 CDM
  SG_ HDC_Activation : 15|2@0+ (1,0) [0|0] "" VDC

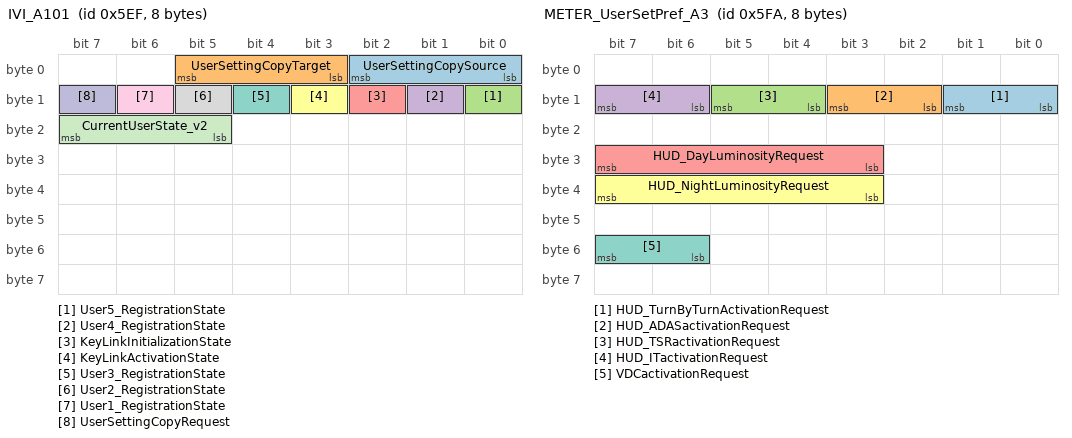
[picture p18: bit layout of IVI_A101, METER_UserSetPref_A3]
BO_ 1519 IVI_A101: 8 CDM
  SG_ UserSettingCopySource : 2|3@0+ (1,0) [0|0] "" HUD
  SG_ UserSettingCopyTarget : 5|3@0+ (1,0) [0|0] "" HUD
  SG_ User5_RegistrationState : 8|1@0+ (1,0) [0|0] "" HUD
  SG_ User4_RegistrationState : 9|1@0+ (1,0) [0|0] "" HUD
  SG_ KeyLinkInitializationState : 10|1@0+ (1,0) [0|0] "" HUD
  SG_ KeyLinkActivationState : 11|1@0+ (1,0) [0|0] "" HUD
  SG_ User3_RegistrationState : 12|1@0+ (1,0) [0|0] "" HUD
  SG_ User2_RegistrationState : 13|1@0+ (1,0) [0|0] "" HUD
  SG_ User1_RegistrationState : 14|1@0+ (1,0) [0|0] "" HUD
  SG_ UserSettingCopyRequest : 15|1@0+ (1,0) [0|0] "" HUD
  SG_ CurrentUserState_v2 : 23|3@0+ (1,0) [0|0] "" HUD

BO_ 1529 IVI_UserSetPref_A3: 8 CDM
  SG_ HUD_ActivationRequest2 : 3|2@0+ (1,0) [0|0] "" HUD
  SG_ HUD_PositionRequest2 : 23|5@0+ (1,0) [0|0] "" HUD
  SG_ HUD_NightLuminosityRequest2 : 39|5@0+ (1,0) [0|0] "" HUD

BO_ 1530 METER_UserSetPref_A3: 8 CDM
  SG_ HUD_TurnByTurnActivationRequest : 9|2@0+ (1,0) [0|0] "" HUD
  SG_ HUD_ADASactivationRequest : 11|2@0+ (1,0) [0|0] "" HUD
  SG_ HUD_TSRactivationRequest : 13|2@0+ (1,0) [0|0] "" HUD
  SG_ HUD_ITactivationRequest : 15|2@0+ (1,0) [0|0] "" HUD
  SG_ HUD_DayLuminosityRequest : 31|5@0+ (1,0) [0|0] "" HUD
  SG_ HUD_NightLuminosityRequest : 39|5@0+ (1,0) [0|0] "" HUD
  SG_ VDCactivationRequest : 55|2@0+ (1,0) [0|0] "" EBAM,VDC

BO_ 1537 ADAS_A119: 8 CDM
  SG_ NoEntry_AlertDisplay : 2|1@0+ (1,0) [0|0] "" HUD
  SG_ ADAS_ModeDisplay : 7|2@0+ (1,0) [0|0] "" HUD
  SG_ NoEntry_Alert : 8|1@0+ (1,0) [0|0] "" HUD
  SG_ ACC_TargetDistanceAlert : 10|2@0+ (1,0) [0|0] "" HUD
  SG_ ACC_DistanceOverrideDisplay : 11|1@0+ (1,0) [0|0] "" HUD
  SG_ ACC_SpeedOverrideDisplay : 12|1@0+ (1,0) [0|0] "" HUD
  SG_ ACC_TargetDistanceDisplay : 15|3@0+ (1,0) [0|0] "" HUD
  SG_ ACC_DynTargetDistanceDisplay : 23|8@0+ (1,0) [0|255] "wu" HUD
  SG_ ACC_SpeedSettingDisplay : 31|8@0+ (1,0) [0|255] "wu" HUD
  SG_ ACC_DistanceSettingDisplay : 39|3@0+ (1,0) [0|0] "" HUD
  SG_ LCA_FailureDisplay : 41|2@0+ (1,0) [0|0] "" HUD
  SG_ LCA_OverrideDisplay : 42|1@0+ (1,0) [0|0] "" HUD
  SG_ LCA_SteeringWheelDisplay : 46|2@0+ (1,0) [0|0] "" HUD
  SG_ LDP_StatusDisplay : 49|2@0+ (1,0) [0|0] "" HUD
  SG_ LDP_LaneDisplay : 51|2@0+ (1,0) [0|0] "" HUD
  SG_ LDP_AlertStatus : 54|2@0+ (1,0) [0|0] "" HUD
  SG_ DriverGuideDisplay : 63|3@0+ (1,0) [0|0] "" HUD

BO_ 1538 ADAS_A120: 8 CDM
  SG_ LKA_OvertimeAlert : 19|1@0+ (1,0) [0|0] "" HUD
  SG_ LDW_AlertStatus : 21|2@0+ (1,0) [0|0] "" HUD
  SG_ EAP_AlertDisplay : 26|1@0+ (1,0) [0|0] "" HUD
  SG_ LCA_LineCrossingAlert : 39|2@0+ (1,0) [0|0] "" HUD

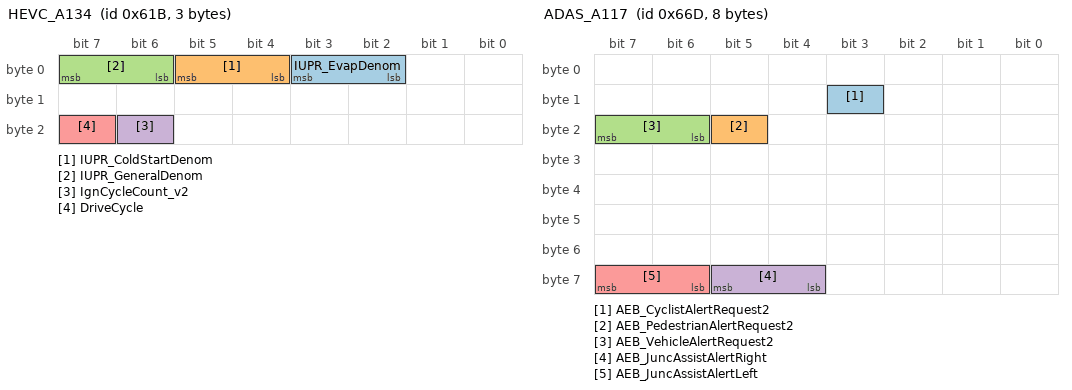
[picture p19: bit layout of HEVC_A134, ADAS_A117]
BO_ 1563 HEVC_A134: 3 CDM
  SG_ IUPR_EvapDenom : 3|2@0+ (1,0) [0|0] "" EBA
  SG_ IUPR_ColdStartDenom : 5|2@0+ (1,0) [0|0] "" EBA
  SG_ IUPR_GeneralDenom : 7|2@0+ (1,0) [0|0] "" EBA
  SG_ IgnCycleCount_v2 : 22|1@0+ (1,0) [0|0] "" EBA
  SG_ DriveCycle : 23|1@0+ (1,0) [0|0] "" EBA

BO_ 1595 IVI_A114: 8 CDM
  SG_ HUD_RotationPositionRequest2 : 19|5@0+ (1,0) [0|0] "" HUD

BO_ 1596 IVI_R103: 8 CDM
  SG_ NextTurnProximityDetected : 0|1@0+ (1,0) [0|0] "" HUD
  SG_ IconNumberForNavigationDisplay : 39|8@0+ (1,0) [0|255] "wu" HUD
  SG_ TCS_DeactivationRequest2 : 45|2@0+ (1,0) [0|0] "" EBAM,VDC
  SG_ HDC_ActivationRequest2 : 47|2@0+ (1,0) [0|0] "" VDC

BO_ 1614 IVI_A129: 8 CDM
  SG_ HUD_TelSMSactivationRequest2 : 1|2@0+ (1,0) [0|0] "" HUD
  SG_ HUD_ITactivationRequest2 : 3|2@0+ (1,0) [0|0] "" HUD

BO_ 1637 CDM_A112: 8 CDM
  SG_ DriveModeState : 28|5@0+ (1,0) [0|0] "" HUD

BO_ 1645 ADAS_A117: 8 CDM
  SG_ AEB_CyclistAlertRequest2 : 11|1@0+ (1,0) [0|0] "" HUD
  SG_ AEB_PedestrianAlertRequest2 : 21|1@0+ (1,0) [0|0] "" HUD
  SG_ AEB_VehicleAlertRequest2 : 23|2@0+ (1,0) [0|0] "" HUD
  SG_ AEB_JuncAssistAlertRight : 61|2@0+ (1,0) [0|0] "" HUD
  SG_ AEB_JuncAssistAlertLeft : 63|2@0+ (1,0) [0|0] "" HUD

BO_ 1659 HFM_A102: 5 CDM
  SG_ UserIdentification_IKeyLink : 7|3@0+ (1,0) [0|0] "" HUD

BO_ 1720 METER_UserSetPref_A6: 3 CDM
  SG_ HUD_TelSMSactivationRequest : 11|2@0+ (1,0) [0|0] "" HUD

BO_ 1738 METER_A105: 8 CDM
  SG_ HUD_UpDownRequest : 25|2@0+ (1,0) [0|0] "" HUD

BO_ 1763 METER_UserSetPref_A102: 1 CDM
  SG_ HUD_RotationPositionRequest : 7|5@0+ (1,0) [0|0] "" HUD

BO_ 1765 SWA_ConfigFrame: 8 CDM
  SG_ SWA_Config : 7|64@0+ (1,0) [0|0] "" EBAM,VDC

BO_ 1772 METER_A110: 8 CDM
  SG_ HUD_SSAActivationRequest : 11|2@0+ (1,0) [0|0] "" HUD
  SG_ HUD_SonarActivationRequest : 13|2@0+ (1,0) [0|0] "" HUD
  SG_ HUD_ShiftActivationRequest : 15|2@0+ (1,0) [0|0] "" HUD

BO_ 1925 DTOOL_to_HNS: 8 CDM
  SG_ DTOOL_to_HNS : 7|64@0+ (1,0) [0|0] "" HNS

BO_ 1957 HNS_to_DTOOL: 8 HNS
  SG_ HNS_to_DTOOL : 7|64@0+ (1,0) [0|0] "" CDM

BO_ 1984 STRG_DiagnosisInfo_Frame: 4 EBAM
  SG_ STRG_DiagnosisInfo : 7|16@0+ (1,0) [0|65535] "-" CDM

BO_ 2563507968 SIGMA_CDMTriggerFrame: 7 CDM
  SG_ SIGMA_CDM : 4|29@0+ (1,0) [0|0] "" EBA,HNS,HUD
  SG_ SIGMA_DTCCDM : 39|24@0+ (1,0) [0|0] "" EBA,HNS,HUD

BO_ 2563508007 SIGMA_eHBoxTriggerFrame: 7 CDM
  SG_ SIGMA_eHBox : 4|29@0+ (1,0) [0|0] "" EBA,HNS,HUD
  SG_ SIGMA_DTCeHBox : 39|24@0+ (1,0) [0|0] "" EBA,HNS,HUD

BO_ 2563508009 SIGMA_PSD_RTriggerFrame: 7 CDM
  SG_ SIGMA_PSD_R : 4|29@0+ (1,0) [0|0] "" EBA,HNS,HUD
  SG_ SIGMA_DTCPSD_R : 39|24@0+ (1,0) [0|0] "" EBA,HNS,HUD

BO_ 2563508019 SIGMA_PBDTriggerFrame: 7 CDM
  SG_ SIGMA_PBD : 4|29@0+ (1,0) [0|0] "" EBA,HNS,HUD
  SG_ SIGMA_DTCPBD : 39|24@0+ (1,0) [0|0] "" EBA,HNS,HUD

BO_ 2563508021 SIGMA_RADARTriggerFrame: 7 CDM
  SG_ SIGMA_RADAR : 4|29@0+ (1,0) [0|0] "" EBA,HNS,HUD
  SG_ SIGMA_DTCRADAR : 39|24@0+ (1,0) [0|0] "" EBA,HNS,HUD

BO_ 2563508022 SIGMA_PSCUTriggerFrame: 7 CDM
  SG_ SIGMA_PSCU : 4|29@0+ (1,0) [0|0] "" EBA,HNS,HUD
  SG_ SIGMA_DTCPSCU : 39|24@0+ (1,0) [0|0] "" EBA,HNS,HUD

BO_ 2563508030 SIGMA_SRad_RLTriggerFrame: 7 CDM
  SG_ SIGMA_SRad_RL : 4|29@0+ (1,0) [0|0] "" EBA,HNS,HUD
  SG_ SIGMA_DTCSRad_RL : 39|24@0+ (1,0) [0|0] "" EBA,HNS,HUD

BO_ 2563508035 SIGMA_eRDC_LTriggerFrame: 7 CDM
  SG_ SIGMA_eRDC_L : 4|29@0+ (1,0) [0|0] "" EBA,HNS,HUD
  SG_ SIGMA_DTCeRDC_L : 39|24@0+ (1,0) [0|0] "" EBA,HNS,HUD

BO_ 2563508037 SIGMA_eRDC_RTriggerFrame: 7 CDM
  SG_ SIGMA_eRDC_R : 4|29@0+ (1,0) [0|0] "" EBA,HNS,HUD
  SG_ SIGMA_DTCeRDC_R : 39|24@0+ (1,0) [0|0] "" EBA,HNS,HUD

BO_ 2563508042 SIGMA_ANCTriggerFrame: 7 CDM
  SG_ SIGMA_ANC : 4|29@0+ (1,0) [0|0] "" EBA,HNS,HUD
  SG_ SIGMA_DTCANC : 39|24@0+ (1,0) [0|0] "" EBA,HNS,HUD

BO_ 2563508064 SIGMA_VDCTriggerFrame: 7 CDM
  SG_ SIGMA_VDC : 4|29@0+ (1,0) [0|0] "" EBA,HNS,HUD
  SG_ SIGMA_DTCVDC : 39|24@0+ (1,0) [0|0] "" EBA,HNS,HUD

BO_ 2563508066 SIGMA_EPSTriggerFrame: 7 CDM
  SG_ SIGMA_EPS : 4|29@0+ (1,0) [0|0] "" EBA,HNS,HUD
  SG_ SIGMA_DTCEPS : 39|24@0+ (1,0) [0|0] "" EBA,HNS,HUD

BO_ 2563508067 SIGMA_METERTriggerFrame: 7 CDM
  SG_ SIGMA_METER : 4|29@0+ (1,0) [0|0] "" EBA,HNS,HUD
  SG_ SIGMA_DTCMETER : 39|24@0+ (1,0) [0|0] "" EBA,HNS,HUD

BO_ 2563508068 SIGMA_HVACTriggerFrame: 7 CDM
  SG_ SIGMA_HVAC : 4|29@0+ (1,0) [0|0] "" EBA,HNS,HUD
  SG_ SIGMA_DTCHVAC : 39|24@0+ (1,0) [0|0] "" EBA,HNS,HUD

BO_ 2563508069 SIGMA_BCMTriggerFrame: 7 CDM
  SG_ SIGMA_BCM : 4|29@0+ (1,0) [0|0] "" EBA,HNS,HUD
  SG_ SIGMA_DTCBCM : 39|24@0+ (1,0) [0|0] "" EBA,HNS,HUD

BO_ 2563508071 SIGMA_IVITriggerFrame: 7 CDM
  SG_ SIGMA_IVI : 4|29@0+ (1,0) [0|0] "" EBA,HNS,HUD
  SG_ SIGMA_DTCIVI : 39|24@0+ (1,0) [0|0] "" EBA,HNS,HUD

BO_ 2563508072 SIGMA_4WDTriggerFrame: 7 CDM
  SG_ SIGMA_4WD : 4|29@0+ (1,0) [0|0] "" EBA,HNS,HUD
  SG_ SIGMA_DTC4WD : 39|24@0+ (1,0) [0|0] "" EBA,HNS,HUD

BO_ 2563508077 SIGMA_USMTriggerFrame: 7 CDM
  SG_ SIGMA_USM : 4|29@0+ (1,0) [0|0] "" EBA,HNS,HUD
  SG_ SIGMA_DTCUSM : 39|24@0+ (1,0) [0|0] "" EBA,HNS,HUD

BO_ 2563508078 SIGMA_SONARTriggerFrame: 7 CDM
  SG_ SIGMA_SONAR : 4|29@0+ (1,0) [0|0] "" EBA,HNS,HUD
  SG_ SIGMA_DTCSONAR : 39|24@0+ (1,0) [0|0] "" EBA,HNS,HUD

BO_ 2563508079 SIGMA_DSMUTriggerFrame: 7 CDM
  SG_ SIGMA_DSMU : 4|29@0+ (1,0) [0|0] "" EBA,HNS,HUD
  SG_ SIGMA_DTCDSMU : 39|24@0+ (1,0) [0|0] "" EBA,HNS,HUD

BO_ 2563508082 SIGMA_ACUTriggerFrame: 7 CDM
  SG_ SIGMA_ACU : 4|29@0+ (1,0) [0|0] "" EBA,HNS,HUD
  SG_ SIGMA_DTCACU : 39|24@0+ (1,0) [0|0] "" EBA,HNS,HUD

BO_ 2563508089 SIGMA_PSD_LTriggerFrame: 7 CDM
  SG_ SIGMA_PSD_L : 4|29@0+ (1,0) [0|0] "" EBA,HNS,HUD
  SG_ SIGMA_DTCPSD_L : 39|24@0+ (1,0) [0|0] "" EBA,HNS,HUD

BO_ 2563508093 SIGMA_ADASTriggerFrame: 7 CDM
  SG_ SIGMA_ADAS : 4|29@0+ (1,0) [0|0] "" EBA,HNS,HUD
  SG_ SIGMA_DTCADAS : 39|24@0+ (1,0) [0|0] "" EBA,HNS,HUD

BO_ 2563508099 SIGMA_A_IVCTriggerFrame: 7 CDM
  SG_ SIGMA_A_IVC : 4|29@0+ (1,0) [0|0] "" EBA,HNS,HUD
  SG_ SIGMA_DTCA_IVC : 39|24@0+ (1,0) [0|0] "" EBA,HNS,HUD

BO_ 2563508108 SIGMA_INV_METriggerFrame: 7 CDM
  SG_ SIGMA_INV_ME : 4|29@0+ (1,0) [0|0] "" EBA,HNS,HUD
  SG_ SIGMA_DTCINV_ME : 39|24@0+ (1,0) [0|0] "" EBA,HNS,HUD

BO_ 2563508115 SIGMA_OBC_ACTriggerFrame: 7 CDM
  SG_ SIGMA_OBC_AC : 4|29@0+ (1,0) [0|0] "" EBA,HNS,HUD
  SG_ SIGMA_DTCOBC_AC : 39|24@0+ (1,0) [0|0] "" EBA,HNS,HUD

BO_ 2563508122 SIGMA_HEVCTriggerFrame: 7 CDM
  SG_ SIGMA_HEVC : 4|29@0+ (1,0) [0|0] "" EBA,HNS,HUD
  SG_ SIGMA_DTCHEVC : 39|24@0+ (1,0) [0|0] "" EBA,HNS,HUD

BO_ 2563508130 SIGMA_AUDIOampTriggerFrame: 7 CDM
  SG_ SIGMA_AUDIOamp : 4|29@0+ (1,0) [0|0] "" EBA,HNS,HUD
  SG_ SIGMA_DTCAUDIOamp : 39|24@0+ (1,0) [0|0] "" EBA,HNS,HUD

BO_ 2563508133 SIGMA_HNSTriggerFrame: 7 HNS
  SG_ SIGMA_HNS : 4|29@0+ (1,0) [0|0] "" CDM,EBA,HUD
  SG_ SIGMA_DTCHNS : 39|24@0+ (1,0) [0|0] "" CDM,EBA,HUD

BO_ 2563508139 SIGMA_VKMTriggerFrame: 7 CDM
  SG_ SIGMA_VKM : 4|29@0+ (1,0) [0|0] "" EBA,HNS,HUD
  SG_ SIGMA_DTCVKM : 39|24@0+ (1,0) [0|0] "" EBA,HNS,HUD

BO_ 2563508153 SIGMA_HFMTriggerFrame: 7 CDM
  SG_ SIGMA_HFM : 4|29@0+ (1,0) [0|0] "" EBA,HNS,HUD
  SG_ SIGMA_DTCHFM : 39|24@0+ (1,0) [0|0] "" EBA,HNS,HUD

BO_ 2563508154 SIGMA_AVMTriggerFrame: 7 CDM
  SG_ SIGMA_AVM : 4|29@0+ (1,0) [0|0] "" EBA,HNS,HUD
  SG_ SIGMA_DTCAVM : 39|24@0+ (1,0) [0|0] "" EBA,HNS,HUD

BO_ 2563508157 SIGMA_SCUTriggerFrame: 7 CDM
  SG_ SIGMA_SCU : 4|29@0+ (1,0) [0|0] "" EBA,HNS,HUD
  SG_ SIGMA_DTCSCU : 39|24@0+ (1,0) [0|0] "" EBA,HNS,HUD

BO_ 2563508164 SIGMA_eShifterTriggerFrame: 7 CDM
  SG_ SIGMA_eShifter : 4|29@0+ (1,0) [0|0] "" EBA,HNS,HUD
  SG_ SIGMA_DTCeShifter : 39|24@0+ (1,0) [0|0] "" EBA,HNS,HUD

BO_ 2563508181 SIGMA_SRad_RRTriggerFrame: 7 CDM
  SG_ SIGMA_SRad_RR : 4|29@0+ (1,0) [0|0] "" EBA,HNS,HUD
  SG_ SIGMA_DTCSRad_RR : 39|24@0+ (1,0) [0|0] "" EBA,HNS,HUD

BO_ 2563508189 SIGMA_FrCameraTriggerFrame: 7 CDM
  SG_ SIGMA_FrCamera : 4|29@0+ (1,0) [0|0] "" EBA,HNS,HUD
  SG_ SIGMA_DTCFrCamera : 39|24@0+ (1,0) [0|0] "" EBA,HNS,HUD

BO_ 2563508200 SIGMA_ECMTriggerFrame: 7 CDM
  SG_ SIGMA_ECM : 4|29@0+ (1,0) [0|0] "" EBA,HNS,HUD
  SG_ SIGMA_DTCECM : 39|24@0+ (1,0) [0|0] "" EBA,HNS,HUD

BO_ 2563508201 SIGMA_ATCUTriggerFrame: 7 CDM
  SG_ SIGMA_ATCU : 4|29@0+ (1,0) [0|0] "" EBA,HNS,HUD
  SG_ SIGMA_DTCATCU : 39|24@0+ (1,0) [0|0] "" EBA,HNS,HUD

BO_ 2563508205 SIGMA_BMS_HVTriggerFrame: 7 CDM
  SG_ SIGMA_BMS_HV : 4|29@0+ (1,0) [0|0] "" EBA,HNS,HUD
  SG_ SIGMA_DTCBMS_HV : 39|24@0+ (1,0) [0|0] "" EBA,HNS,HUD

BO_ 2563508207 SIGMA_INV_HSGTriggerFrame: 7 CDM
  SG_ SIGMA_INV_HSG : 4|29@0+ (1,0) [0|0] "" EBA,HNS,HUD
  SG_ SIGMA_DTCINV_HSG : 39|24@0+ (1,0) [0|0] "" EBA,HNS,HUD

BO_ 2563567883 SIGMA_BMS_12VTriggerFrame: 7 CDM
  SG_ SIGMA_BMS_12V : 4|29@0+ (1,0) [0|0] "" EBA,HNS,HUD
  SG_ SIGMA_DTCBMS_12V : 39|24@0+ (1,0) [0|0] "" EBA,HNS,HUD

BO_ 2563567951 SIGMA_EPS_subTriggerFrame: 7 CDM
  SG_ SIGMA_EPS_sub : 4|29@0+ (1,0) [0|0] "" EBA,HNS,HUD
  SG_ SIGMA_DTCEPS_sub : 39|24@0+ (1,0) [0|0] "" EBA,HNS,HUD

BO_ 2563567958 SIGMA_eShiftActTriggerFrame: 7 CDM
  SG_ SIGMA_eShiftAct : 4|29@0+ (1,0) [0|0] "" EBA,HNS,HUD
  SG_ SIGMA_DTCeShiftAct : 39|24@0+ (1,0) [0|0] "" EBA,HNS,HUD

BO_ 2563567968 SIGMA_HUDTriggerFrame: 7 HUD
  SG_ SIGMA_HUD : 4|29@0+ (1,0) [0|0] "" CDM,EBA,HNS
  SG_ SIGMA_DTCHUD : 39|24@0+ (1,0) [0|0] "" CDM,EBA,HNS

BO_ 2563568024 SIGMA_HPCUTriggerFrame: 7 CDM
  SG_ SIGMA_HPCU : 4|29@0+ (1,0) [0|0] "" EBA,HNS,HUD
  SG_ SIGMA_DTCHPCU : 39|24@0+ (1,0) [0|0] "" EBA,HNS,HUD

BO_ 2563568093 SIGMA_DCDC_HVTriggerFrame: 7 CDM
  SG_ SIGMA_DCDC_HV : 4|29@0+ (1,0) [0|0] "" EBA,HNS,HUD
  SG_ SIGMA_DTCDCDC_HV : 39|24@0+ (1,0) [0|0] "" EBA,HNS,HUD

BO_ 2563568098 SIGMA_EBATriggerFrame: 7 EBA
  SG_ SIGMA_EBA : 4|29@0+ (1,0) [0|0] "" CDM,HNS,HUD
  SG_ SIGMA_DTCEBA : 39|24@0+ (1,0) [0|0] "" CDM,HNS,HUD

BO_ 2563568101 SIGMA_INV_RETriggerFrame: 7 CDM
  SG_ SIGMA_INV_RE : 4|29@0+ (1,0) [0|0] "" EBA,HNS,HUD
  SG_ SIGMA_DTCINV_RE : 39|24@0+ (1,0) [0|0] "" EBA,HNS,HUD

BO_ 2563568130 SIGMA_AirSUSPTriggerFrame: 7 CDM
  SG_ SIGMA_AirSUSP : 4|29@0+ (1,0) [0|0] "" EBA,HNS,HUD
  SG_ SIGMA_DTCAirSUSP : 39|24@0+ (1,0) [0|0] "" EBA,HNS,HUD

BO_ 2563568148 SIGMA_BSGTriggerFrame: 7 CDM
  SG_ SIGMA_BSG : 4|29@0+ (1,0) [0|0] "" EBA,HNS,HUD
  SG_ SIGMA_DTCBSG : 39|24@0+ (1,0) [0|0] "" EBA,HNS,HUD

BO_ 2563568163 SIGMA_SRad_FL_TriggerFrame: 7 CDM
  SG_ SIGMA_SRad_FL : 4|29@0+ (1,0) [0|0] "" EBA,HNS,HUD
  SG_ SIGMA_DTCSRad_FL : 39|24@0+ (1,0) [0|0] "" EBA,HNS,HUD

BO_ 2563568164 SIGMA_SRad_FRTriggerFrame: 7 CDM
  SG_ SIGMA_SRad_FR : 4|29@0+ (1,0) [0|0] "" EBA,HNS,HUD
  SG_ SIGMA_DTCSRad_FR : 39|24@0+ (1,0) [0|0] "" EBA,HNS,HUD

BO_ 2563568201 SIGMA_STBWTriggerFrame: 7 CDM
  SG_ SIGMA_STBW : 4|29@0+ (1,0) [0|0] "" EBA,HNS,HUD
  SG_ SIGMA_DTCSTBW : 39|24@0+ (1,0) [0|0] "" EBA,HNS,HUD

BO_ 2563568233 SIGMA_DMCTriggerFrame: 7 CDM
  SG_ SIGMA_DMC : 4|29@0+ (1,0) [0|0] "" EBA,HNS,HUD
  SG_ SIGMA_DTCDMC : 39|24@0+ (1,0) [0|0] "" EBA,HNS,HUD

BO_ 2563568267 SIGMA_RSCU3RTriggerFrame: 7 CDM
  SG_ SIGMA_RSCU3R : 4|29@0+ (1,0) [0|0] "" EBA,HNS,HUD
  SG_ SIGMA_DTCRSCU3R : 39|24@0+ (1,0) [0|0] "" EBA,HNS,HUD

BO_ 2563568288 SIGMA_BLM_RPKTriggerFrame: 7 CDM
  SG_ SIGMA_BLM_RPK : 4|29@0+ (1,0) [0|0] "" EBA,HNS,HUD
  SG_ SIGMA_DTCBLM_RPK : 39|24@0+ (1,0) [0|0] "" EBA,HNS,HUD

BO_ 2563568290 SIGMA_SCCMTriggerFrame: 7 CDM
  SG_ SIGMA_SCCM : 4|29@0+ (1,0) [0|0] "" EBA,HNS,HUD
  SG_ SIGMA_DTCSCCM : 39|24@0+ (1,0) [0|0] "" EBA,HNS,HUD

BO_ 2563568300 SIGMA_RSCU2RTriggerFrame: 7 CDM
  SG_ SIGMA_RSCU2R : 4|29@0+ (1,0) [0|0] "" EBA,HNS,HUD
  SG_ SIGMA_DTCRSCU2R : 39|24@0+ (1,0) [0|0] "" EBA,HNS,HUD

BO_ 2564448497 DTOOL_to_HUDextd: 8 CDM
  SG_ DTOOL_to_HUDextd : 7|64@0+ (1,0) [0|0] "" HUD

BO_ 2564481777 DTOOL_to_EBAextd: 8 CDM
  SG_ DTOOL_to_EBAextd : 7|64@0+ (1,0) [0|0] "" EBA

BO_ 2564485472 HUD_to_DTOOLextd: 8 HUD
  SG_ HUD_to_DTOOLextd : 7|64@0+ (1,0) [0|0] "" CDM

BO_ 2564485602 EBA_to_DTOOLextd: 8 EBA
  SG_ EBA_to_DTOOLextd : 7|64@0+ (1,0) [0|0] "" CDM

BO_ 2564502513 DTOOL_to_ALLUCEOBDExtd: 8 CDM
  SG_ DTOOL_to_ALLUCEOBD : 7|64@0+ (1,0) [0|0] "" EBA

BO_ 2609102859 CDM_WakeUpFrame_CH2_extd: 2 CDM
  SG_ CDM_WakeUp_Signal : 7|16@0+ (1,0) [0|0] "" EBA,EBAM

BO_ 2615042289 FTOOLS_CGWtoHUD: 8 CDM
  SG_ FTOOLS_CGWtoHUD : 7|64@0+ (1,0) [0|0] "" HUD

BO_ 2615079264 FTOOLS_HUDtoCGW: 8 HUD
  SG_ FTOOLS_HUDtoCGW : 7|64@0+ (1,0) [0|0] "" CDM

BO_TX_BU_ 114 : EBA,EBAM;
BO_TX_BU_ 165 : EBAM,VDC;
BO_TX_BU_ 431 : EBAM,VDC;
BO_TX_BU_ 650 : EBAM,VDC;
BO_TX_BU_ 939 : EBA,EBAM;
BO_TX_BU_ 1081 : EBAM,VDC;
BO_TX_BU_ 1984 : EBAM,VDC;

VAL_ 111 SubBrakeAct_Status 0 "Not Active" 1 "Active";
VAL_ 111 LongitudinalControlStatus_EBA 0 "Impossible to execute Longtudinal request" 1 "Longtudinal Braking Fully Operational";
VAL_ 111 AEB_BrakingPerformanceStatus2 0 "Braking fully operational" 1 "Impossible to execute request" 2 "Not used" 3 "Unavailable";
VAL_ 114 EBA_BrakePedalApplied 0 "Not initialized" 1 "Brake pedal not applied" 2 "Brake pedal applied" 3 "Failure";
VAL_ 114 ExternalBrakeStatus 0 "Not initialized" 1 "Not ready" 2 "Ready" 3 "Not used";
VAL_ 114 ExternalBrakeRequestPriority 0 "Driver brake dominates" 1 "External brake dominates";
VAL_ 116 StopAutoPhase 0 "NotInAutoPhase" 1 "StartAuto" 2 "StopAuto" 3 "Not Used" 4 "StopAutoOngoing" 5 "StartByInjectionOnly" 6 "ReflexStart" 7 "Unavailable";
VAL_ 124 ElecBrakeTorqueActuatorStatus 0 "Unavailable" 1 "EVC Available as an actuator" 2 "EVC Not available as an actuator" 3 "CAN communication error from VDC";
VAL_ 159 HBAThresholdRequest2 0 "HBA standard threshold" 1 "HBA low threshold";
VAL_ 159 AEB_BrakeWheelTorqueOrder2 0 "No Brake Request" 1 "Brake Torque AEBS moderate" 2 "Brake Torque AEBS strong" 3 "Brake Torque AEBS city" 4 "Brake Torque AEBS Maximum" 5 "Not used" 6 "Not used" 7 "unavailable";
VAL_ 159 HydraulicPreFillRequest2 0 "Prefill NOT Requested" 1 "Prefill Requested";
VAL_ 159 AEB_BrakeTorqueGainOrder2 0 "Reserved for Safety" 1 "Brake Gain Off" 2 "Brake Gain ON" 3 "Unavailable Value";
VAL_ 165 VDC_DiagToolActive 0 "Not active" 1 "Active";
VAL_ 165 Rr_RegenBrakeInRegulation 0 "Regen brake control not in regulation" 1 "Regen brake control in regulation" 2 "Not Used" 3 "Unavailable";
VAL_ 168 SwaSensorInternalStatus 0 "not calibrated, not indexed" 1 "not calibrated, indexed" 2 "fault" 3 "reserved" 4 "calibrated, not initialised" 5 "calibrated, initialised" 6 "reserved" 7 "reserved";
VAL_ 336 SubAD_ADmodeStatus 0 "AD/RPK OFF" 1 "AD2 L2 regulation" 2 "AD1 L3 regulation" 3 "RPK regulation" 4 "AD/RPK OFF + TD or MRM in regulation" 5 "AD2 L2 regulation + TD or MRM in regulation" 6 "AD1 L3 regulation + TD or MRM in regulation" 7 "RPK regulation + TD or MRM in regulation";
VAL_ 354 PathChangeRequest2 0 "No Request" 1 "Request";
VAL_ 357 Global_BrakeWheelTorqueOrder_RD 0 "No brake request" 1 "ACC/AD brake request" 2 "HFPB/FullAPK brake request" 3 "Not used" 4 "Not used" 5 "Not used" 6 "Not used" 7 "Not used";
VAL_ 357 AEB_BrakeWheelTorqueOrder_RD 0 "No Brake Request" 1 "Brake Torque AEBS moderate" 2 "Brake Torque AEBS strong" 3 "Brake Torque AEBS city" 4 "Brake Torque AEBS Maximum" 5 "Not used" 6 "Not used" 7 "unavailable";
VAL_ 366 DriverTargetBrakingStatus 0 "Not enable" 1 "Enable";
VAL_ 366 PotentialReductionPressureStatus 0 "Not enable" 1 "Enable";
VAL_ 366 ActuatorCircuitStatus 0 "Without pressure" 1 "With pressure";
VAL_ 374 ABSavailable 0 "Not available" 1 "Available";
VAL_ 374 ModulationPressureOrder 0 "Not Enable" 1 "Enable";
VAL_ 374 LongitudinalControlActuatorMode 0 "Not used" 1 "EBA actuation mode ON" 2 "EBA actuation mode OFF" 3 "Unavailable";
VAL_ 374 SuctionSupportOrder 0 "Not active" 1 "Active";
VAL_ 374 LongitudinalControlGradientOrder 0 "Dynamic" 1 "Standard" 2 "Comfort Low" 3 "Comfort Medium" 4 "Comfort Max" 5 "SSA hold" 6 "Not used" 7 "Unavailable";
VAL_ 431 RegenBrakeMalfunction_VDC 0 "No failure" 1 "Failure detected";
VAL_ 431 ABSinRegulation_CRBS 0 "no ABS regulation" 1 "ABS in regulation";
VAL_ 431 RegenBrakeInRegulation 0 "Not used" 1 "Regen brake control not in regulation" 2 "Regen brake control in regulation" 3 "Unavailable";
VAL_ 431 CaliperPlungerPressureStatus 0 "No Pressure" 1 "RR wheel" 2 "RL wheel" 3 "RL/RR wheels" 4 "FR wheel" 5 "FR/RR wheels" 6 "FR/RL wheels" 7 "FR/RL/RR wheels" 8 "FL wheel" 9 "FL/RR wheels" 10 "FL/RLwheels" 11 "FL/RL/RR wheels" 12 "FL/FR wheels" 13 "FL/FR/RR wheels" 14 "FL/FR/RL wheels" 15 "All wheels";
VAL_ 431 EBA_SmoothStartRequest 0 "no request" 1 "speed limitation request";
VAL_ 431 EBA_MotorLimitationRequest 0 "Not Active" 1 "Active";
VAL_ 464 Global_SteeringAngleOrder_RD 0 "No request" 1 "Request";
VAL_ 464 ADmodeStatus_RD 0 "AD/RPK OFF" 1 "AD2 L2 regulation" 2 "AD1 L3 regulation" 3 "RPK regulation" 4 "AD/RPK OFF + TD or MRM in regulation" 5 "AD2 L2 regulation + TD or MRM in regulation" 6 "AD1 L3 regulation + TD or MRM in regulation" 7 "RPK regulation + TD or MRM in regulation";
VAL_ 590 WheelDirectionRR2 0 "No movement detected yet" 1 "Wheel Front Direction" 2 "Wheel Rear Direction" 3 "Unavailable";
VAL_ 590 WheelDirectionRL2 0 "No movement detected yet" 1 "Wheel Front Direction" 2 "Wheel Rear Direction" 3 "Unavailable";
VAL_ 592 BrakePedalPressedByDriver2 0 "Not used" 1 "Brake Pedal Not Pressed" 2 "Brake Pedal Pressed" 3 "Unavailable";
VAL_ 592 ABSinRegulation2 0 "no ABS regulation" 1 "ABS in regulation";
VAL_ 650 VehicleSpeedClock 0 "This counter is incremented when CAN buffers are updated";
VAL_ 732 ParkingBrakeBindingStatus_RD 0 "Brake released" 1 "Brake tightened" 2 "Not used" 3 "Unavailable";
VAL_ 747 DiffLockOperatingFlag 0 "Diff Lock not operating" 1 "Diff Lock operating";
VAL_ 747 DiffLockControllerFailure 0 "Diff Lock Controller Operational" 1 "Diff Lock Controller Failure";
VAL_ 747 DiffLockSwitching_EDL 0 "Diff lock switching OFF" 1 "Diff lock switching ON";
VAL_ 772 AD_SteeringAngleDisplay 0 "Normal  0deg" 1 "Normal  0deg" 2 "Normal  0deg" 3 "Normal  0deg" 4 "Normal  0deg" 5 "Normal  0deg" 6 "Normal  0deg" 7 "Normal  0deg" 8 "Left 120  minus180deg" 9 "Left 119  minus178.5deg" 10 "Left 118  minus177deg" 11 "Left 117  minus175.5deg" 12 "Left 116  minus174deg" 13 "Left 115  minus172.5deg" 14 "Left 114  minus171deg" 15 "Left 113  minus169.5deg" 16 "Left 112  minus168deg" 17 "Left 111  minus166.5deg" 18 "Left 110  minus165deg" 19 "Left 109  minus163.5deg" 20 "Left 108  minus162deg" 21 "Left 107  minus160.5deg" 22 "Left 106  minus159deg" 23 "Left 105  minus157.5deg" 24 "Left 104  minus156deg" 25 "Left 103  minus154.5deg" 26 "Left 102  minus153deg" 27 "Left 101  minus151.5deg" 28 "Left 100  minus150deg" 29 "Left 99  minus148.5deg" 30 "Left 98  minus147deg" 31 "Left 97  minus145.5deg" 32 "Left 96  minus144deg" 33 "Left 95  minus142.5deg" 34 "Left 94  minus141deg" 35 "Left 93  minus139.5deg" 36 "Left 92  minus138deg" 37 "Left 91  minus136.5deg" 38 "Left 90  minus135deg" 39 "Left 89  minus133.5deg" 40 "Left 88  minus132deg" 41 "Left 87  minus130.5deg" 42 "Left 86  minus129deg" 43 "Left 85  minus127.5deg" 44 "Left 84  minus126deg" 45 "Left 83  minus124.5deg" 46 "Left 82  minus123deg" 47 "Left 81  minus121.5deg" 48 "Left 80  minus120deg" 49 "Left 79  minus118.5deg" 50 "Left 78  minus117deg" 51 "Left 77  minus115.5deg" 52 "Left 76  minus114deg" 53 "Left 75  minus112.5deg" 54 "Left 74  minus111deg" 55 "Left 73  minus109.5deg" 56 "Left 72  minus108deg" 57 "Left 71  minus106.5deg" 58 "Left 70  minus105deg" 59 "Left 69  minus103.5deg" 60 "Left 68  minus102deg" 61 "Left 67  minus100.5deg" 62 "Left 66  minus99deg" 63 "Left 65  minus97.5deg" 64 "Left 64  minus96deg" 65 "Left 63  minus94.5deg" 66 "Left 62  minus93deg" 67 "Left 61  minus91.5deg" 68 "Left 60  minus90deg" 69 "Left 59  minus88.5deg" 70 "Left 58  minus87deg" 71 "Left 57  minus85.5deg" 72 "Left 56  minus84deg" 73 "Left 55  minus82.5deg" 74 "Left 54  minus81deg" 75 "Left 53  minus79.5deg" 76 "Left 52  minus78deg" 77 "Left 51  minus76.5deg" 78 "Left 50  minus75deg" 79 "Left 49  minus73.5deg" 80 "Left 48  minus72deg" 81 "Left 47  minus70.5deg" 82 "Left 46  minus69deg" 83 "Left 45  minus67.5deg" 84 "Left 44  minus66deg" 85 "Left 43  minus64.5deg" 86 "Left 42  minus63deg" 87 "Left 41  minus61.5deg" 88 "Left 40  minus60deg" 89 "Left 39  minus58.5deg" 90 "Left 38  minus57deg" 91 "Left 37  minus55.5deg" 92 "Left 36  minus54deg" 93 "Left 35  minus52.5deg" 94 "Left 34  minus51deg" 95 "Left 33  minus49.5deg" 96 "Left 32  minus48deg" 97 "Left 31  minus46.5deg" 98 "Left 30  minus45deg" 99 "Left 29  minus43.5deg" 100 "Left 28  minus42deg" 101 "Left 27  minus40.5deg" 102 "Left 26  minus39deg" 103 "Left 25  minus37.5deg" 104 "Left 24  minus36deg" 105 "Left 23  minus34.5deg" 106 "Left 22  minus33deg" 107 "Left 21  minus31.5deg" 108 "Left 20  minus30deg" 109 "Left 19  minus28.5deg" 110 "Left 18  minus27deg" 111 "Left 17  minus25.5deg" 112 "Left 16  minus24deg" 113 "Left 15  minus22.5deg" 114 "Left 14  minus21deg" 115 "Left 13  minus19.5deg" 116 "Left 12  minus18deg" 117 "Left 11  minus16.5deg" 118 "Left 10  minus15deg" 119 "Left 9  minus13.5deg" 120 "Left 8  minus12deg" 121 "Left 7  minus10.5deg" 122 "Left 6  minus9deg" 123 "Left 5  minus7.5deg" 124 "Left 4  minus6deg" 125 "Left 3  minus4.5deg" 126 "Left 2  minus3deg" 127 "Left 1  minus1.5deg" 128 "Normal  0deg" 129 "Right 1  plus1.5deg" 130 "Right 2  plus3deg" 131 "Right 3  plus4.5deg" 132 "Right 4  plus6deg" 133 "Right 5  plus7.5deg" 134 "Right 6  plus9deg" 135 "Right 7  plus10.5deg" 136 "Right 8  plus12deg" 137 "Right 9  plus13.5deg" 138 "Right 10  plus15deg" 139 "Right 11  plus16.5deg" 140 "Right 12  plus18deg" 141 "Right 13  plus19.5deg" 142 "Right 14  plus21deg" 143 "Right 15  plus22.5deg" 144 "Right 16  plus24deg" 145 "Right 17  plus25.5deg" 146 "Right 18  plus27deg" 147 "Right 19  plus28.5deg" 148 "Right 20  plus30deg" 149 "Right 21  plus31.5deg" 150 "Right 22  plus33deg" 151 "Right 23  plus34.5deg" 152 "Right 24  plus36deg" 153 "Right 25  plus37.5deg" 154 "Right 26  plus39deg" 155 "Right 27  plus40.5deg" 156 "Right 28  plus42deg" 157 "Right 29  plus43.5deg" 158 "Right 30  plus45deg" 159 "Right 31  plus46.5deg" 160 "Right 32  plus48deg" 161 "Right 33  plus49.5deg" 162 "Right 34  plus51deg" 163 "Right 35  plus52.5deg" 164 "Right 36  plus54deg" 165 "Right 37  plus55.5deg" 166 "Right 38  plus57deg" 167 "Right 39  plus58.5deg" 168 "Right 40  plus60deg" 169 "Right 41  plus61.5deg" 170 "Right 42  plus63deg" 171 "Right 43  plus64.5deg" 172 "Right 44  plus66deg" 173 "Right 45  plus67.5deg" 174 "Right 46  plus69deg" 175 "Right 47  plus70.5deg" 176 "Right 48  plus72deg" 177 "Right 49  plus73.5deg" 178 "Right 50  plus75deg" 179 "Right 51  plus76.5deg" 180 "Right 52  plus78deg" 181 "Right 53  plus79.5deg" 182 "Right 54  plus81deg" 183 "Right 55  plus82.5deg" 184 "Right 56  plus84deg" 185 "Right 57  plus85.5deg" 186 "Right 58  plus87deg" 187 "Right 59  plus88.5deg" 188 "Right 60  plus90deg" 189 "Right 61  plus91.5deg" 190 "Right 62  plus93deg" 191 "Right 63  plus94.5deg" 192 "Right 64  plus96deg" 193 "Right 65  plus97.5deg" 194 "Right 66  plus99deg" 195 "Right 67  plus100.5deg" 196 "Right 68  plus102deg" 197 "Right 69  plus103.5deg" 198 "Right 70  plus105deg" 199 "Right 71  plus106.5deg" 200 "Right 72  plus108deg" 201 "Right 73  plus109.5deg" 202 "Right 74  plus111deg" 203 "Right 75  plus112.5deg" 204 "Right 76  plus114deg" 205 "Right 77  plus115.5deg" 206 "Right 78  plus117deg" 207 "Right 79  plus118.5deg" 208 "Right 80  plus120deg" 209 "Right 81  plus121.5deg" 210 "Right 82  plus123deg" 211 "Right 83  plus124.5deg" 212 "Right 84  plus126deg" 213 "Right 85  plus127.5deg" 214 "Right 86  plus129deg" 215 "Right 87  plus130.5deg" 216 "Right 88  plus132deg" 217 "Right 89  plus133.5deg" 218 "Right 90  plus135deg" 219 "Right 91  plus136.5deg" 220 "Right 92  plus138deg" 221 "Right 93  plus139.5deg" 222 "Right 94  plus141deg" 223 "Right 95  plus142.5deg" 224 "Right 96  plus144deg" 225 "Right 97  plus145.5deg" 226 "Right 98  plus147deg" 227 "Right 99  plus148.5deg" 228 "Right 100  plus150deg" 229 "Right 101  plus151.5deg" 230 "Right 102  plus153deg" 231 "Right 103  plus154.5deg" 232 "Right 104  plus156deg" 233 "Right 105  plus157.5deg" 234 "Right 106  plus159deg" 235 "Right 107  plus160.5deg" 236 "Right 108  plus162deg" 237 "Right 109  plus163.5deg" 238 "Right 110  plus165deg" 239 "Right 111  plus166.5deg" 240 "Right 112  plus168deg" 241 "Right 113  plus169.5deg" 242 "Right 114  plus171deg" 243 "Right 115  plus172.5deg" 244 "Right 116  plus174deg" 245 "Right 117  plus175.5deg" 246 "Right 118  plus177deg" 247 "Right 119  plus178.5deg" 248 "Right 120  plus180deg" 249 "Normal  0deg" 250 "Normal  0deg" 251 "Normal  0deg" 252 "Normal  0deg" 253 "Normal  0deg" 254 "Normal  0deg" 255 "Normal  0deg";
VAL_ 930 DMC_UnresponsiveAlertStatus 0 "No display" 1 "Fatigue_Lv1" 2 "Drowsiness_Lv1" 3 "Fatigue_Lv2" 4 "Drowsiness_Lv2" 5 "Duration" 6 "Stopped" 7 "Reserved";
VAL_ 939 EBA_MinorFailure 0 "No Alert" 1 "DLC failure alert request";
VAL_ 939 EBAtoBeCalibrated 0 "No warning : ECU operational" 1 "ECU to be calibrated warning";
VAL_ 939 EBAinCalibratingDiag 0 "No ABS or ESP in Calibrating Diagnosis Session warning" 1 "ABS or ESP in Calibrating Diagnosis Session warning";
VAL_ 939 EBA_MILlamp 0 "MIL lamp display not requested" 1 "MIL lamp display requested";
VAL_ 939 EBA_MajorFailure 0 "No Failure" 1 "Failure";
VAL_ 939 HBCrequest_RCY 0 "No HBC support request" 1 "HBC full support request";
VAL_ 939 MiniBrakeFluidLevelAlertDisp_EBA 0 "No alert" 1 "Alert Mini brake fluid level";
VAL_ 939 EBA_BoosterPowerCaution 0 "Buzzer off" 1 "Buzzer on";
VAL_ 944 RPES_Status 0 "Not available" 1 "RPES_Forbidden" 2 "RPES_Wait_For_Req" 3 "RPES_StartInProgress" 4 "RPES_EngineRunning" 5 "RPES_Interrupt" 6 "Not Used" 7 "Not Used";
VAL_ 961 DistanceBeforeNextAction 0 "Table Value26873";
VAL_ 961 UnitDistanceBeforeNextAction 0 "meter" 1 "kilometer" 2 "yard" 3 "mile" 4 "feet" 5 "not used" 6 "not used" 7 "not used" 8 "not used" 9 "not used" 10 "not used" 11 "not used" 12 "not used" 13 "not used" 14 "not used" 15 "not used";
VAL_ 967 TPW_ResetDriverRequest2 0 "Unavailable" 1 "TPW Reset driver NOT requested" 2 "TPW Reset driver requested" 3 "Not used";
VAL_ 967 HUD_UpDownRequest2 0 "No request" 1 "Up command requested" 2 "Down command requested" 3 "Reset request";
VAL_ 972 AD_TransitionState 0 "No display" 1 "AD1 to AD2L2 HandsON" 2 "AD2L2 HandsON to AD1" 3 "AD2L2 HandsON to AD2L2 HandsOFF" 4 "AD2L2 HandsON to AD1L3" 5 "AD2L2 HandsOFF to AD2L2 HandsON" 6 "AD2L2 HandsOFF to AD1" 7 "AD2L2 HandsOFF to AD1L3" 8 "AD1L3 to AD2L2 HandsOFF" 9 "AD1L3 to AD2L2 HandsON" 10 "AD1L3 to AD1" 11 "Not used" 12 "Not used" 13 "Not used" 14 "Not used" 15 "Not used";
VAL_ 972 ALC_GapLeftDisplay 0 "No display" 1 "Very Near" 2 "Near" 3 "Far" 4 "Very Far" 5 "Not used" 6 "Not used" 7 "Not used";
VAL_ 972 AD2L2_HOFF_TransitonState 0 "No display" 1 "User activation : OFF to AD2L2_HOFF ON NotOperational" 2 "System activation : ON NotOperational to Operational" 3 "User deactivation : ON NotOperational to OFF" 4 "User deactivation : ON Operational to OFF" 5 "System deactivation lvl1 ON NotOperational to OFF" 6 "System deactivation lvl2 ON NotOperational to OFF" 7 "System deactivation lvl1 ON Operational to ON NotOperational" 8 "System deactivation lvl2 ON Operational to ON NotOperational" 9 "System deactivation lvl1 ON Operational to OFF" 10 "System deactivation lvl2 ON Operational to OFF" 11 "Not used" 12 "Not used" 13 "Not used" 14 "Not used" 15 "Not used" 16 "Not used" 17 "Not used" 18 "Not used" 19 "Not used" 20 "Not used" 21 "Not used" 22 "Not used" 23 "Not used" 24 "Not used" 25 "Not used" 26 "Not used" 27 "Not used" 28 "Not used" 29 "Not used" 30 "Not used" 31 "Not used";
VAL_ 972 ALC_GapRightDisplay 0 "No display" 1 "Very Near" 2 "Near" 3 "Far" 4 "Very Far" 5 "Not used" 6 "Not used" 7 "Not used";
VAL_ 972 AD2L2_HON_TransitonState 0 "No display" 1 "User activation OFF to AD2L2_HON ON NotOperational" 2 "System activation : ON NotOperational to ON Operational" 3 "User deactivation : NotOperational to OFF" 4 "User deactivation : ON Operational to OFF" 5 "System deactivation lvl1: ON NotOperational to OFF" 6 "System deactivation lvl2 : ON NotOperational to OFF" 7 "System deactivation lvl1 : ON Operational to ON NotOperational" 8 "System deactivation lvl2 ON Operational to ON NotOperational" 9 "System deactivation lvl1 ON Operational to OFF" 10 "System deactivation lvl2 ON Operational to OFF" 11 "Not used" 12 "Not used" 13 "Not used" 14 "Not used" 15 "Not used" 16 "Not used" 17 "Not used" 18 "Not used" 19 "Not used" 20 "Not used" 21 "Not used" 22 "Not used" 23 "Not used" 24 "Not used" 25 "Not used" 26 "Not used" 27 "Not used" 28 "Not used" 29 "Not used" 30 "Not used" 31 "Not used";
VAL_ 972 ADL3_MRM 0 "No display" 1 "Alert Eyes on road level1" 2 "Alert Eyes on road level2" 3 "Alert Eyes on road level3" 4 "Alert Eyes on road level4" 5 "Alert Eyes on road level5" 6 "Alert Eyes on road level6" 7 "Alert Eyes on road level7" 8 "Alert Eyes on road level8" 9 "Alert Eyes on road level9" 10 "Alert Eyes on road level10" 11 "Alert Eyes on road level11" 12 "Alert Eyes on road level12" 13 "Alert Eyes on road level13" 14 "Alert Eyes on road level14" 15 "Alert Eyes on road level15" 16 "Alert Eyes not on road level1" 17 "Alert Eyes not on road level2" 18 "Alert Eyes not on road level3" 19 "Alert Eyes not on road level4" 20 "Alert Eyes not on road level5" 21 "Alert Eyes not on road level6" 22 "Alert Eyes not on road level7" 23 "Alert Eyes not on road level8" 24 "Alert Eyes not on road level9" 25 "Alert Eyes not on road level10" 26 "Alert Eyes not on road level11" 27 "Alert Eyes not on road level12" 28 "Alert Eyes not on road level13" 29 "Alert Eyes not on road level14" 30 "Alert Eyes not on road level15" 31 "Alert Eyes not on road level16";
VAL_ 972 ADL3_TransitionState 0 "No display" 1 "User activation : OFF to NotOperational Available wo Longi" 2 "User deactivation : NotOperational Available to OFF" 3 "NotOperational Available wo Longi to NotOperational Available w Longi" 4 "NotOperational Available w Longi to NotOperational Available wo Longi" 5 "NotOperational Available w Longi to OFF" 6 "NotOperational Available w Longi to ON Ready" 7 "ON Ready to NotOperational Available w Longi" 8 "ON Ready to NotOperational Available wo Longi" 9 "ON Ready to OFF" 10 "ON Ready to ON Operational" 11 "ON Operational to ON Ready level1" 12 "ON Operational to ON Ready level2" 13 "ON Operational to NotOperational Available w Longi level1" 14 "ON Operational to NotOperational Available w Longi level2" 15 "ON Operational to NotOperational Available wo Longi level1" 16 "ON Operational to NotOperational Available wo Longi level2" 17 "ON Operational to OFF level1" 18 "ON Operational to OFF level2" 19 "Not used" 20 "Not used" 21 "Not used" 22 "Not used" 23 "Not used" 24 "Not used" 25 "Not used" 26 "Not used" 27 "Not used" 28 "Not used" 29 "Not used" 30 "Not used" 31 "Not used";
VAL_ 972 AD_CutinLeftDisplay 0 "No display" 1 "Motorbike Alert without risk" 2 "Motorbike Alert with risk" 3 "Truck Alert without risk" 4 "Truck Alert with risk" 5 "Car Alert without risk" 6 "Car Alert with risk" 7 "Unknown Alert without risk" 8 "Unknown Alert with risk" 9 "Not used" 10 "Not used" 11 "Not used" 12 "Not used" 13 "Not used" 14 "Not used" 15 "Not used";
VAL_ 972 ALC_Direction 0 "Right Heading Lane Change" 1 "Left Heading Lane Change";
VAL_ 972 AD_CancelReasonRER 0 "No request" 1 "Reemission request";
VAL_ 972 AD_CutinRightDisplay 0 "No display" 1 "Motorbike Alert without risk" 2 "Motorbike Alert with risk" 3 "Truck Alert without risk" 4 "Truck Alert with risk" 5 "Car Alert without risk" 6 "Car Alert with risk" 7 "Unknown Alert without risk" 8 "Unknown Alert with risk" 9 "Not used" 10 "Not used" 11 "Not used" 12 "Not used" 13 "Not used" 14 "Not used" 15 "Not used";
VAL_ 974 ParkingBrakeBindingRequest_RD 0 "No parking brake binding requested" 1 "Parking brake binding requested";
VAL_ 976 SubAD_ADL3_MRM 0 "No display" 1 "Alert Eyes on road level1" 2 "Alert Eyes on road level2" 3 "Alert Eyes on road level3" 4 "Alert Eyes on road level4" 5 "Alert Eyes on road level5" 6 "Alert Eyes on road level6" 7 "Alert Eyes on road level7" 8 "Alert Eyes on road level8" 9 "Alert Eyes on road level9" 10 "Alert Eyes on road level10" 11 "Alert Eyes on road level11" 12 "Alert Eyes on road level12" 13 "Alert Eyes on road level13" 14 "Alert Eyes on road level14" 15 "Alert Eyes on road level15" 16 "Alert Eyes not on road level1" 17 "Alert Eyes not on road level2" 18 "Alert Eyes not on road level3" 19 "Alert Eyes not on road level4" 20 "Alert Eyes not on road level5" 21 "Alert Eyes not on road level6" 22 "Alert Eyes not on road level7" 23 "Alert Eyes not on road level8" 24 "Alert Eyes not on road level9" 25 "Alert Eyes not on road level10" 26 "Alert Eyes not on road level11" 27 "Alert Eyes not on road level12" 28 "Alert Eyes not on road level13" 29 "Alert Eyes not on road level14" 30 "Alert Eyes not on road level15" 31 "Alert Eyes not on road level16";
VAL_ 976 SubAD_AD2_HandsOff_MRM 0 "No display" 1 "Alert Eyes on road level1" 2 "Alert Eyes on road level2" 3 "Alert Eyes on road level3" 4 "Alert Eyes on road level4" 5 "Alert Eyes on road level5" 6 "Alert Eyes on road level6" 7 "Alert Eyes on road level7" 8 "Alert Eyes on road level8" 9 "Alert Eyes on road level9" 10 "Alert Eyes on road level10" 11 "Alert Eyes on road level11" 12 "Alert Eyes on road level12" 13 "Alert Eyes on road level13" 14 "Alert Eyes on road level14" 15 "Alert Eyes on road level15" 16 "Alert Eyes not on road level1" 17 "Alert Eyes not on road level2" 18 "Alert Eyes not on road level3" 19 "Alert Eyes not on road level4" 20 "Alert Eyes not on road level5" 21 "Alert Eyes not on road level6" 22 "Alert Eyes not on road level7" 23 "Alert Eyes not on road level8" 24 "Alert Eyes not on road level9" 25 "Alert Eyes not on road level10" 26 "Alert Eyes not on road level11" 27 "Alert Eyes not on road level12" 28 "Alert Eyes not on road level13" 29 "Alert Eyes not on road level14" 30 "Alert Eyes not on road level15" 31 "Alert Eyes not on road level16";
VAL_ 976 SubAD_AD_MRM_PhaseCounter 0 "No display";
VAL_ 977 HNS_Opening_Request 0 "Forced open is not requested" 1 "Forced open is requested";
VAL_ 977 HNS_Diagnostic_Req 0 "Diagnosis is inhibited" 1 "Diagnosis is permitted";
VAL_ 986 ALC_Marker 0 "No display" 1 "Right NotOperational" 2 "Right Waiting wo GapConfirmation" 3 "Right Waiting w GapConfirmation" 4 "Right Operational wo GapConfirmation" 5 "Right Operational w GapConfirmation" 6 "Left NotOperational" 7 "Left Waiting wo GapConfirmation" 8 "Left Waiting w GapConfirmation" 9 "Left Operational wo GapConfirmation" 10 "Left Operational w GapConfirmation" 11 "Not used" 12 "Not used" 13 "Not used" 14 "Not used" 15 "Not used";
VAL_ 986 ALC_Request 0 "No request" 1 "Initial User Request" 2 "Initial System Request" 3 "Second User request" 4 "Second System request" 5 "Not used" 6 "Not used" 7 "Not used";
VAL_ 986 ALC_Distance 0 "No Display";
VAL_ 986 AD2_HandsOff_MRM 0 "No display" 1 "Alert Eyes on road level1" 2 "Alert Eyes on road level2" 3 "Alert Eyes on road level3" 4 "Alert Eyes on road level4" 5 "Alert Eyes on road level5" 6 "Alert Eyes on road level6" 7 "Alert Eyes on road level7" 8 "Alert Eyes on road level8" 9 "Alert Eyes on road level9" 10 "Alert Eyes on road level10" 11 "Alert Eyes on road level11" 12 "Alert Eyes on road level12" 13 "Alert Eyes on road level13" 14 "Alert Eyes on road level14" 15 "Alert Eyes on road level15" 16 "Alert Eyes not on road level1" 17 "Alert Eyes not on road level2" 18 "Alert Eyes not on road level3" 19 "Alert Eyes not on road level4" 20 "Alert Eyes not on road level5" 21 "Alert Eyes not on road level6" 22 "Alert Eyes not on road level7" 23 "Alert Eyes not on road level8" 24 "Alert Eyes not on road level9" 25 "Alert Eyes not on road level10" 26 "Alert Eyes not on road level11" 27 "Alert Eyes not on road level12" 28 "Alert Eyes not on road level13" 29 "Alert Eyes not on road level14" 30 "Alert Eyes not on road level15" 31 "Alert Eyes not on road level16";
VAL_ 986 AD_AvailabilityLevel 0 "No display" 1 "AD Availability Level1 (dn)" 2 "AD Availability Level2 (up/dn)" 3 "AD Availability Level3" 4 "AD Availability Level4" 5 "AD Availability Level5" 6 "AD Availability Level6 (up/dn)" 7 "AD Availability Level7 (up/dn)" 8 "AD Availability Level8 (dn)" 9 "AD Availability Level9 (dn)" 10 "AD Availability Level10 (up/dn)" 11 "AD Availability Level11 (up)" 12 "Not used" 13 "Not used" 14 "Not used" 15 "Not used";
VAL_ 986 AD_MRM_PhaseCounter 0 "No display";
VAL_ 986 AD_RealisticScreenEffect 0 "No Effect" 1 "Effect1" 2 "Effect2" 3 "Effect3" 4 "Effect4" 5 "Effect5" 6 "Not Used" 7 "Not Used";
VAL_ 1003 AD_LeadingVehicleStatus 0 "No Display" 1 "Far Motor bike" 2 "Near Motor bike" 3 "Far Truck" 4 "Near Truck" 5 "Far Car" 6 "Near Car" 7 "Far Unknown vehicle" 8 "Near Unknown vehicle" 9 "Reserved" 10 "Reserved" 11 "Reserved" 12 "Reserved" 13 "Reserved" 14 "Reserved" 15 "Reserved";
VAL_ 1003 AD_DivideLineStatus 0 "No Display" 1 "AD condition Not fulfilled" 2 "AD condition fulfilled" 3 "AD continuous condition fulfilled";
VAL_ 1003 AD_SteeringWheelTakeOverAlert 0 "No Alert" 1 "Alert level1" 2 "Alert level2" 3 "Alert level3" 4 "Alert level4" 5 "Alert level5" 6 "Alert level6" 7 "Alert level7";
VAL_ 1003 AD_StatusDisplay 0 "No display" 1 "AD2L2 HON NotOperational" 2 "AD2L2 HON Operational" 3 "AD2L2 HOFF NotOperational" 4 "AD2L2 HOFF Operational" 5 "AD1L3 NotOperational Available wo Longi" 6 "AD1L3 NotOperational Available w Longi" 7 "AD1L3 Ready" 8 "AD1L3 Operational" 9 "AD_TemporaryFailure" 10 "AD_PermanentFailure" 11 "Not used" 12 "Not used" 13 "Not used" 14 "Not used" 15 "Not used";
VAL_ 1003 ALC_HandsRequest 0 "Hands NotRequested" 1 "Hands Requested without risk" 2 "Hands Requested with risk" 3 "Not used";
VAL_ 1003 ALC_Warning 0 "No display" 1 "Warning Level1 (low risk)" 2 "Warning Level2 (high risk)" 3 "Not used";
VAL_ 1003 ALC_StatusDisplay 0 "No display" 1 "Not Operational" 2 "Operational waiting HandsON" 3 "Operational waiting HandsOFF" 4 "Operational Active HandsON" 5 "Operational Active HandsOFF" 6 "Operational Standby" 7 "Not used";
VAL_ 1003 AD_FunctionalLimit 0 "Limit not reached" 1 "Limit reached without risk" 2 "Limit reached with risk" 3 "Not used";
VAL_ 1003 AD2_Routeguide 0 "No Display" 1 "ON NotOperational" 2 "ON Operational HandsON" 3 "ON Operational HandsOFF" 4 "Not used" 5 "Not used" 6 "Not used" 7 "Reserved";
VAL_ 1021 HNS_PowernetDiagnosis 0 "nominal" 1 "PWA undervoltage detected" 2 "PWA overvoltage detected" 3 "PWB undervoltage detected";
VAL_ 1021 HNS_Failure_status 0 "Initialization" 1 "Diagnosis requested" 2 "No failure" 3 "Failure";
VAL_ 1021 HNS_StopAutoForbidden 0 "Stop Auto forbidden" 1 "Stop Auto authorized";
VAL_ 1021 HNS_Switching_Status 0 "Diagnosis on going" 1 "Open" 2 "Closed" 3 "Invalid";
VAL_ 1068 AnticipatedElectricGearChange 0 "No Change" 1 "Change in progress with regenerative braking";
VAL_ 1068 VehicleTractionMode 0 "Vehicle not in traction mode" 1 "Vehicle in charge" 2 "Vehicle in full electric mode" 3 "Vehicle in hybrid serial mode" 4 "Vehicle in thermic mode" 5 "Vehicle in hybrid parallel mode" 6 "Not Used" 7 "Unavailable value";
VAL_ 1070 OBDWarmUpCycleDet 0 "Warm Up Cycle is not completed" 1 "Warm Up Cycle is completed";
VAL_ 1070 OBDPrmtDelCdn 0 "OBD PDTC Delete Condition not deteted" 1 "OBD PDTC Delete Condition deteted";
VAL_ 1070 OBD_Ready_On 0 "HEV system is in the state of Not-Ready-mode." 1 "HEV system is in the state of Ready-mode.";
VAL_ 1081 TCS_DeactivationState 0 "TCS not deactivated" 1 "TCS deactivated";
VAL_ 1081 VDC_Deactivated 0 "VDC available" 1 "VDC disable";
VAL_ 1081 HDC_status_information 0 "HDC Not activated" 1 "HDC Activated" 2 "HDC in Control" 3 "HDC Failure";
VAL_ 1081 SSA_StateLamp_byVDC 0 "No display and No LED" 1 "SSA Lamp STANDBY and LED" 2 "SSA Lamp ON (HOLD) and LED" 3 "No display and LED";
VAL_ 1081 SSA_NotImmobilizedVehicleWarning 0 "No warning Vehicle not immobilized display request" 1 "Warning Vehicle not immobilized display request";
VAL_ 1081 SSA_DeactiveDispReq 0 "No request" 1 "Display request";
VAL_ 1081 DiffLockSwitching_VDC 0 "Diff lock switching OFF" 1 "Diff lock switching ON";
VAL_ 1081 SideWindAssistActivationDispReq 0 "No display" 1 "Display Side Wind Assist";
VAL_ 1081 HDC_ActivationRefusedDisplay 0 "HDC_ActivationRefused not displayed" 1 "HDC_ActivationRefused displayed";
VAL_ 1081 TCS_DeactivationStateToMETER 0 "No display" 1 "TCS ASR is activated text on and no telltale display" 2 "TCS ASR is deactivated text on and telltale display" 3 "TCS ASR deactivated no text message and telltale display";
VAL_ 1081 BrakePadWear_byEBAM 0 "no fault" 1 "short circuit 12 V" 2 "pad to be changed" 3 "Unavailable";
VAL_ 1081 ExtendedGripModeDisplayRequest 0 "No display ExtendedGrip not available" 1 "Mode 1" 2 "Mode 2" 3 "Mode 3" 4 "Mode 4" 5 "Mode 5" 6 "Not Used" 7 "Not Used";
VAL_ 1099 AT_GearShiftRefused 0 "gear shift accepted" 1 "gear shift refused";
VAL_ 1099 ATCVT_RangeIndicationExtended 0 "OFF" 1 "P range" 2 "R range" 3 "N range" 4 "D range" 5 "S range" 6 "L range" 7 "B range" 8 "1st range" 9 "2nd range" 10 "3rd range" 11 "4th range" 12 "5th range" 13 "6th range" 14 "7th range" 15 "8th range" 16 "9th range" 17 "10th range" 18 "Not used" 19 "Not used" 20 "M1st" 21 "M2nd" 22 "M3rd" 23 "M4th" 24 "M5th" 25 "M6th" 26 "M7th" 27 "M8th" 28 "M9th" 29 "M10th" 30 "Not used" 31 "Not used" 32 "Auto 1st" 33 "Auto 2nd" 34 "Auto 3rd" 35 "Auto 4th" 36 "Auto 5th" 37 "Auto 6th" 38 "Auto 7th" 39 "Auto 8th" 40 "Auto 9th" 41 "Auto 10th" 42 "Not used" 43 "Not used" 44 "Not used" 45 "Not used" 46 "Not used" 47 "Not used" 48 "Not used" 49 "Not used" 50 "Not used" 51 "Not used" 52 "Not used" 53 "Not used" 54 "Not used" 55 "Not used" 56 "Not used" 57 "Not used" 58 "Not used" 59 "Not used" 60 "Not used" 61 "Not used" 62 "Not used" 63 "Not used";
VAL_ 1101 FlashingIndicatorStatusDisplay 0 "left and right flashing indicators OFF" 1 "left flashing indicator ON and right flashing indicator OFF" 2 "left flashing indicator OFF and right flashing indicator ON" 3 "left flashing indicator ON and right flashing indicator ON" 4 "Not used" 5 "Not used" 6 "Not used" 7 "Unavailable";
VAL_ 1105 DisplayedSpeedUnit 0 "Speed Unit in kmph" 1 "Speed Unit in mph";
VAL_ 1105 GlobalVehicleWarningState 0 "No global  vehicle  Fault" 1 "SERV is ON (alert type R3)" 2 "STOP is ON (alert type D3)" 3 "SERV and STOP are ON (alert type R3& D3)";
VAL_ 1105 DayNightForBacklights 0 "Day" 1 "Twilight" 2 "Night" 3 "Unavailable";
VAL_ 1105 LowBrakeFluidLevelStatus 0 "Unavailable" 1 "No brake system malfunction" 2 "Brake system malfunction" 3 "Not used";
VAL_ 1107 IgnitionSupplyConfirmation 0 "no primary ignition supply" 1 "primary ignition supply on";
VAL_ 1108 Storage12V_SwitchRequest 0 "Disconnection request" 1 "Connection request";
VAL_ 1110 BMS12V_SwitchState 0 "Opened" 1 "Closed";
VAL_ 1110 BMS12V_StorageFailure 0 "Limit mode" 1 "Failure mode" 2 "Nominal mode" 3 "Not used";
VAL_ 1116 SSA_StateLamp 0 "No display" 1 "SSA Lamp STANDBY" 2 "SSA Lamp ON (HOLD)" 3 "Not used";
VAL_ 1137 RequestedSpeedDisplayRequest 254 "CC/SL off or awaiting for a speed selection" 255 "CC/SL failure";
VAL_ 1137 Maintenance_Mode_Status 0 "not used" 1 "no request" 2 "request" 3 "unavailable";
VAL_ 1137 CruiseControlStatus 0 "Cruise Control (CC) and Speed Limit (SL) OFF" 1 "SL active" 2 "SL on and (awaiting or suspended)" 3 "SL requested and in failure" 4 "CC active" 5 "CC ON and ( awaiting  or suspended)" 6 "CC requested and in failure" 7 "Vehicle not equipped with CC/SL / Not available";
VAL_ 1138 OverspeedIndicationDisplayReq 0 "No CC/SL over speed indication display requested" 1 "CC/SL over speed indication display requested";
VAL_ 1138 OverSpeedAlert_SL 0 "No involuntary SL over speed warning requested" 1 "Involuntary SL over speed warning requested";
VAL_ 1139 Rr_TransmRangeEngaged_Current 0 "declutched at rest" 1 "1st range" 2 "2nd range" 3 "Unavailable";
VAL_ 1139 Rr_TransmRangeEngaged_Target 0 "declutched at rest" 1 "1st range" 2 "2nd range" 3 "Unavailable";
VAL_ 1140 LKA_AlertStatus 0 "No alert" 1 "Right alert" 2 "Left alert" 3 "Not used";
VAL_ 1140 LKA_SWheelTakeOverAlert_v3 0 "No Alert" 1 "Alert Lvl 1" 2 "Alert Lvl 2" 3 "Alert Lvl 3" 4 "Alert Lvl 4" 5 "Alert Lvl 5" 6 "Not used" 7 "Not used";
VAL_ 1143 RESstatus 0 "Unavailable" 1 "Reserved for safety" 2 "Reserved for safety" 3 "Normal engine start only" 4 "Reserved for safety" 5 "Reserved for safety" 6 "wait for RES / Presoak" 7 "Reserved for safety" 8 "Reserved for safety" 9 "Customer Starting" 10 "Reserved for safety" 11 "Reserved for safety" 12 "Remote Engine Start" 13 "Reserved for safety" 14 "Reserved for safety" 15 "Vehicle without RES";
VAL_ 1143 DriverStopRequestWhileBattOff 0 "Unavailable" 1 "Reserved for safety" 2 "no engine stop requested by driver on disconnected 12V battery" 3 "Reserved for safety" 4 "Reserved for safety" 5 "Engine stop requested by driver on disconnected 12V battery" 6 "Reserved for safety" 7 "Reserved for safety";
VAL_ 1143 DriverSeatBeltFailureState 0 "No Monitoring" 1 "Supposed Driver Seat Belt Failure" 2 "Driver Seat Belt OK" 3 "Not used";
VAL_ 1143 StartingMode_BCM 0 "Powertrain Stopped Request" 1 "No request" 2 "Ignition Request" 3 "Starting Request";
VAL_ 1143 DriverDoorState 0 "Unavailable Value" 1 "Driver door closed" 2 "Driver door open" 3 "Not Used";
VAL_ 1143 DriverSeatSensor 0 "Unavailable" 1 "Driver on seat detected" 2 "Driver on seat not detected" 3 "Not used";
VAL_ 1143 PassengerDoorState 0 "Unavailable Value" 1 "Passenger door closed" 2 "Passenger door open" 3 "Not used";
VAL_ 1145 ProbableCustomerFeedBackNeed 0 "Customer feedback probably not needed" 1 "Customer feedback needed";
VAL_ 1145 AutoACC2Status_MM 0 "Multimedia is done" 1 "Multimedia can receive / send messages" 2 "Multimedia can detect manual operation" 3 "Multimedia can work for all functions";
VAL_ 1146 EngineStopDriverRequested 0 "no engine stop requested by driver" 1 "nominal engine stop requested by driver";
VAL_ 1146 DriverSafetyBeltBuckleState 0 "SB Not monitored" 1 "SB unfastened" 2 "SB fastened" 3 "Unavailable";
VAL_ 1146 ClutchSwitchMinimumTravel 0 "Not used" 1 "Clutch pedal not pressed" 2 "Clutch pedal pressed at minimum" 3 "Unavailable";
VAL_ 1146 VehicleStates 0 "Sleeping" 1 "Not used" 2 "CutoffPending" 3 "AutoACC  - BatTempoLevel" 4 "Not used" 5 "IgnitionLevel" 6 "StartingInProgress" 7 "PowertrainRunning" 8 "AutoStart" 9 "EngineSystemStop" 10 "Not used" 11 "Not used" 12 "Not used" 13 "Not used" 14 "Not used" 15 "Unavailable";
VAL_ 1146 BrakeInfoStatus 0 "Not used" 1 "Brake pedal not pressed" 2 "Brake pedal pressed" 3 "Not used" 4 "Brake pedal confirmed pressed" 5 "Not used" 6 "Not used" 7 "unavailable";
VAL_ 1146 DeliveryModeInformation_v2 0 "customer mode" 1 "delivery mode level 1" 2 "delivery mode level 2" 3 "Not used";
VAL_ 1146 GADE_v2 0 "Sleep or Crank fault, Disable DiagMuxDTC" 1 "AutoACC fault, Disable DiagMuxDTC" 2 "ALL fault, Disable DiagMuxDTC" 3 "ALL fault, Enable DiagMuxDTC" 4 "FOTA switch fault, Disable DiagMuxDTC" 5 "Not used" 6 "Not used" 7 "Unavailable";
VAL_ 1146 TrailerPresence 0 "no trailer detected" 1 "trailer detected";
VAL_ 1146 DriverDoorStatusSupposedFailure 0 "no supposed Driver's door failure" 1 "supposed driver's door failure";
VAL_ 1146 EngineStopDriverRequestValid 0 "Not Valid" 1 "Valid";
VAL_ 1146 ClutchSwitchMaximumTravel 0 "Not used" 1 "Clutch pedal not pressed at maximum" 2 "Clutch pedal pressed at maximum" 3 "Unavailable";
VAL_ 1149 AD_LaneMarker1_1 0 "No Display" 1 "Line lost" 2 "Solid white" 3 "Dashed white" 4 "Solid yellow without caution" 5 "Solid yellow with caution" 6 "Not used" 7 "Not used";
VAL_ 1149 AD_LaneMarker2_1 0 "No Display" 1 "Line lost" 2 "Solid white" 3 "Dashed white" 4 "Solid yellow without caution" 5 "Solid yellow with caution" 6 "Not used" 7 "Not used";
VAL_ 1149 AD_LaneMarker1_2 0 "No Display" 1 "Line lost" 2 "Solid white" 3 "Dashed white" 4 "Solid yellow without caution" 5 "Solid yellow with caution" 6 "Not used" 7 "Not used";
VAL_ 1149 AD_LaneMarker2_2 0 "No Display" 1 "Line lost" 2 "Solid white" 3 "Dashed white" 4 "Solid yellow without caution" 5 "Solid yellow with caution" 6 "Not used" 7 "Not used";
VAL_ 1149 ALC_TurnByTurnPriority 0 "No priority" 1 "ALC priority";
VAL_ 1149 AD2_ALCGapDetection 0 "No Display" 1 "Preferred lane" 2 "1 time Right ALC to preferred lane" 3 "2 time Right ALC to preferred lane" 4 "3 time Right ALC to preferred lane" 5 "4 time Right ALC to preferred lane" 6 "5 time Right ALC to preferred lane" 7 "6 time Right ALC to preferred lane" 8 "7 time Right ALC to preferred lane" 9 "8 time Right ALC to preferred lane" 10 "1 time Left ALC to preferred lane" 11 "2 time Left ALC to preferred lane" 12 "3 time Left ALC to preferred lane" 13 "4 time Left ALC to preferred lane" 14 "5 time Left ALC to preferred lane" 15 "6 time Left ALC to preferred lane" 16 "7 time Left ALC to preferred lane" 17 "8 time Left ALC to preferred lane" 18 "Not used" 19 "Not used" 20 "Not used" 21 "Not used" 22 "Not used" 23 "Not used" 24 "Not used" 25 "Not used" 26 "Not used" 27 "Not used" 28 "Not used" 29 "Not used" 30 "Not used" 31 "Not used";
VAL_ 1149 AD2_CarPoolLaneNotification 0 "No display" 1 "HOV lane on Right" 2 "HOV lane on Center" 3 "HOV lane on Right and Center" 4 "HOV lane on Left" 5 "HOV lane on Left and Right" 6 "HOV lane on Left and Center" 7 "HOV lane on Left and Center and Right";
VAL_ 1149 AD2_HostVehicleLanePosition 0 "No Display" 1 "1st lane" 2 "2nd lane" 3 "3rd lane" 4 "4th lane" 5 "5th lane" 6 "6th lane" 7 "7th lane" 8 "8th lane" 9 "Not used" 10 "Not used" 11 "Not used" 12 "Not used" 13 "Not used" 14 "Not used" 15 "Not used";
VAL_ 1149 AD2_NumOfLane 0 "No Display" 1 "1 lane" 2 "2 lanes" 3 "3 lanes" 4 "4 lanes" 5 "5 lanes" 6 "6 lanes" 7 "7 lanes" 8 "8 lanes" 9 "Not used" 10 "Not used" 11 "Not used" 12 "Not used" 13 "Not used" 14 "Not used" 15 "Not used";
VAL_ 1176 RMF_StatusDisplay 0 "No display" 1 "Warning" 2 "Intervention1" 3 "Intervention2" 4 "Intervention3" 5 "Intervention4" 6 "Not used" 7 "Unavailable";
VAL_ 1176 RMF_StateDisplayRequest 0 "No display" 1 "Warning" 2 "Intervention1" 3 "Intervention2" 4 "Intervention3" 5 "Intervention4" 6 "Intervention Cancelled" 7 "Recovered" 8 "Not used" 9 "Not used" 10 "Not used" 11 "Not used" 12 "Not used" 13 "Not used" 14 "Not used" 15 "Unavailable";
VAL_ 1176 RMF_FailureDisplay 0 "No display" 1 "RMF Failure1" 2 "RMF Failure2" 3 "RMF Failure3" 4 "Not used" 5 "Not used" 6 "Not used" 7 "Unavailable";
VAL_ 1189 UserIdentification_IKeyLink_v2 0 "No request" 1 "Key No. 1" 2 "Key No. 2" 3 "Key No. 3" 4 "Key No. 4" 5 "Owner Key" 6 "Friend Key ID 1" 7 "Friend Key ID 2" 8 "Friend Key ID 3" 9 "Friend Key ID 4" 10 "Friend Key ID 5" 11 "Not used" 12 "Not used" 13 "Not used" 14 "Not used" 15 "Unavailable";
VAL_ 1278 LCA_WarningStatus 0 "No Display" 1 "Warning only" 2 "Right alert" 3 "Left alert" 4 "Right and left alert" 5 "Not used" 6 "Not used" 7 "Not used";
VAL_ 1299 FKP_ObstacleZone_RF 0 "No detection" 1 "Detect level 1" 2 "Detect level 2" 3 "Detect level 3";
VAL_ 1299 FKP_ObstacleZone_LRC 0 "No detection" 1 "Detect level 1" 2 "Detect level 2" 3 "Detect level 3";
VAL_ 1299 FKP_ObstacleZone_LFC 0 "No detection" 1 "Detect level 1" 2 "Detect level 2" 3 "Detect level 3";
VAL_ 1299 FKP_ObstacleZone_LF 0 "No detection" 1 "Detect level 1" 2 "Detect level 2" 3 "Detect level 3";
VAL_ 1299 FKP_ObstacleZone_RRC 0 "No detection" 1 "Detect level 1" 2 "Detect level 2" 3 "Detect level 3";
VAL_ 1299 FKP_ObstacleZone_RR 0 "No detection" 1 "Detect level 1" 2 "Detect level 2" 3 "Detect level 3";
VAL_ 1299 FKP_ObstacleZone_RL 0 "No detection" 1 "Detect level 1" 2 "Detect level 2" 3 "Detect level 3";
VAL_ 1299 FKP_ObstacleZone_RFC 0 "No detection" 1 "Detect level 1" 2 "Detect level 2" 3 "Detect level 3";
VAL_ 1303 SpeedLimitType 0 "EUR" 1 "USA white(speed limit)" 2 "CANADA white(speed limit)" 3 "USA yellow(speed limit caution)" 4 "CANADA yellow(speed limit caution)" 5 "JAPAN" 6 "CHINA" 7 "AUSTRALIA" 8 "KOREA" 9 "SOUTH AFRICA" 10 "GULF" 11 "Not used" 12 "Not used" 13 "Not used" 14 "Not used" 15 "Unavailable";
VAL_ 1303 TSR_OSP_SubsignZone2 0 "No Display Request" 1 "Generic SubSign Display Request" 2 "Snow Subsign Display Request" 3 "Towing Subsign Display Request" 4 "Arrow Left subsign Display Request" 5 "Arrow Right subsign Display Request" 6 "Truck" 7 "Refer to TSR_OSP_SubsignAdditional_Zone2";
VAL_ 1303 RainSymbolDisplayRequest 0 "No Rain Symbol Display Request" 1 "Rain Symbol Display Request";
VAL_ 1303 OSPConvertedSpeedDisplayRequest 0 "No Display Request" 1 "Converted Speed Display Request";
VAL_ 1303 TSR_OSP_SpeedSignalZone1 254 "Free speed' Symbol" 255 "No Speed available show ---";
VAL_ 1303 TSR_OSP_SpeedSignalZone2 254 "Free speed' Symbol" 255 "No Speed available show ---";
VAL_ 1303 TSR_OSP_SubsignZone1 0 "No Display Request" 1 "Generic SubSign Display Request" 2 "Snow Subsign Display Request" 3 "Towing Subsign Display Request" 4 "Arrow Left subsign Display Request" 5 "Arrow Right subsign Display Request" 6 "Truck" 7 "Refer to TSR_OSP_SubsignAdditional_Zone1";
VAL_ 1303 TSR_OSP_TrafficSignZone3 0 "No display" 1 "No Overtaking Sign" 2 "End Of No Overtaking Sign" 3 "Contextual Traffic Sign 1" 4 "Contextual Traffic Sign 2" 5 "Contextual Traffic Sign 3" 6 "Contextual Traffic Sign 4" 7 "Contextual Traffic Sign 5" 8 "Contextual Traffic Sign 6" 9 "Contextual Traffic Sign 7" 10 "Contextual Traffic Sign 8" 11 "Contextual Traffic Sign 9" 12 "Contextual Traffic Sign 10" 13 "Contextual Traffic Sign 11" 14 "Contextual Traffic Sign 12" 15 "Contextual Traffic Sign 13" 16 "Contextual Traffic Sign 14" 17 "Contextual Traffic Sign 15" 18 "Contextual Traffic Sign 16" 19 "Contextual Traffic Sign 17" 20 "Contextual Traffic Sign 18" 21 "Contextual Traffic Sign 19" 22 "Contextual Traffic Sign 20" 23 "Contextual Traffic Sign 21" 24 "Contextual Traffic Sign 22" 25 "Contextual Traffic Sign 23" 26 "Contextual Traffic Sign 24" 27 "Contextual Traffic Sign 25" 28 "Contextual Traffic Sign 26" 29 "Contextual Traffic Sign 27" 30 "Contextual Traffic Sign 28" 31 "Contextual Traffic Sign 29";
VAL_ 1303 OSPDisplayRequest 0 "No Display Request" 1 "OSP Display Requested";
VAL_ 1303 TSR_OSP_SubsignZone3 0 "No Display Request" 1 "Generic SubSign Display Request" 2 "Snow Subsign Display Request" 3 "Towing Subsign Display Request" 4 "Arrow Left subsign Display Request" 5 "Arrow Right subsign Display Request" 6 "Truck" 7 "Refer to TSR_OSP_SubsignAdditional_Zone3";
VAL_ 1303 OSPOverSpeedDisplayRequest 0 "No Overspeed alert" 1 "OverSpeedAlert";
VAL_ 1303 TSR_OSP_TypeSignalZone2 0 "Normal type" 1 "End of limitation type";
VAL_ 1303 TSR_OSP_TypeSignalZone1 0 "Normal type" 1 "End of limitation type";
VAL_ 1319 GTLN_AlertRequest 0 "No alert" 1 "GTLN level1 alert" 2 "GTLN level2 alert" 3 "GTLN with Distraction";
VAL_ 1319 ADTutorial_GuideDisplay 0 "No display" 1 "Recommend using AD (2steps)" 2 "Recommend using AD (1step)" 3 "Not Used";
VAL_ 1319 eDCA_StatusDisplay 0 "No request" 1 "Standby Status" 2 "Active Status" 3 "Unavailable";
VAL_ 1319 eDCA_NextEvent_Type 0 "No display" 1 "Right curve" 2 "Speed limit" 3 "Road exit right" 4 "Intersection" 5 "Roundabout" 6 "Stop" 7 "Tollbooth" 8 "Yield sign" 9 "Traffic light" 10 "Traffic jam" 11 "Road work" 12 "Left curve" 13 "Multicurve right-left" 14 "Multicurve left-right" 15 "Bump" 16 "T intersection" 17 "Road exit left" 18 "Slippery Road" 19 "End Of Queue" 20 "Stationary Vehicle" 21 "Broken down Vehicle" 22 "Accident Vehicle" 23 "Unknown Obstacle" 24 "Fog" 25 "Heavy Rain" 26 "Traffic light red" 27 "Traffic light green" 28 "Vehicle" 29 "Not used" 30 "Not used" 31 "Unavailable";
VAL_ 1341 UPA_Obstacle_Zone_Front_Right 0 "No detection" 1 "Reserve" 2 "Detect level 2 (70~50cm)" 3 "Detect level 3 (50~30cm)" 4 "Detect level 4 (30~cm)" 5 "Detect level 5" 6 "Reserve" 7 "Unavailable";
VAL_ 1341 UPA_Obstacle_Zone_Front_Left 0 "No detection" 1 "Reserve" 2 "Detect level 2 (70~50cm)" 3 "Detect level 3 (50~30cm)" 4 "Detect level 4 (30~cm)" 5 "Detect level 5" 6 "Reserve" 7 "Unavailable";
VAL_ 1341 UPA_Image_DisplayRequest 0 "No display request" 1 "Rear Detection ON" 2 "Front Detection ON" 3 "Front and Rear Detection ON";
VAL_ 1341 UPA_Obstacle_Zone_Rear_Right 0 "No detection" 1 "Detect level 1 (~70cm)" 2 "Detect level 2 (70~50cm)" 3 "Detect level 3 (50~30cm)" 4 "Detect level 4 (30~cm)" 5 "Detect level 5" 6 "Reserve" 7 "Unavailable";
VAL_ 1341 UPA_Obstacle_Zone_Rear_Left 0 "No detection" 1 "Detect level 1 (~70cm)" 2 "Detect level 2 (70~50cm)" 3 "Detect level 3 (50~30cm)" 4 "Detect level 4 (30~cm)" 5 "Detect level 5" 6 "Reserve" 7 "Unavailable";
VAL_ 1341 UPA_Obstacle_Zone_Rear_Center 0 "No detection" 1 "Detect level 1 (   ~70cm)" 2 "Detect level 2 (70~50cm)" 3 "Detect level 3 (50~30cm)" 4 "Detect level 4 (30~cm)" 5 "Detect level 5" 6 "Reserve" 7 "Unavailable";
VAL_ 1341 UPA_Obstacle_Zone_Front_Center 0 "No detection" 1 "Detect level 1 (   ~70cm)" 2 "Detect level 2 (70~50cm)" 3 "Detect level 3 (50~30cm)" 4 "Detect level 4 (30~cm)" 5 "Detect level 5" 6 "Reserve" 7 "Unavailable";
VAL_ 1341 SensorAvailabilityFrontLeft 0 "Sensor not available" 1 "Sensor available";
VAL_ 1341 SensorAvailabilityFrontCenter 0 "Sensor not available" 1 "Sensor available";
VAL_ 1341 SensorAvailabilityFrontRight 0 "Sensor not available" 1 "Sensor available";
VAL_ 1341 SensorAvailabilityRearRight 0 "Sensor not available" 1 "Sensor available";
VAL_ 1341 SensorAvailabilityRearLeft 0 "Sensor not available" 1 "Sensor available";
VAL_ 1341 SensorAvailabilityRearCenter 0 "Sensor not available" 1 "Sensor available";
VAL_ 1361 ACC_TargetDistanceAlert_v2 0 "No ACC warning" 1 "ACC approach warning" 2 "ACC collision warning" 3 "ACC cancel warning" 4 "ACC alert reminder" 5 "Not used" 6 "Not used" 7 "Not used";
VAL_ 1361 LCDN_AlertRequest 0 "No alert" 1 "LCDN level1 alert" 2 "LCDN level2 alert" 3 "LCDN with Distraction";
VAL_ 1361 AntiUndertake_TargetStatus 0 "No Display" 1 "Right Lane Motor bike" 2 "Left Lane Motor bike" 3 "Right Lane Truck" 4 "Left Lane Truck" 5 "Right Lane Car" 6 "Left Lane Car" 7 "Right Lane Unknown vehicle" 8 "Left Lane Unknown vehicle" 9 "Not used" 10 "Not used" 11 "Not used" 12 "Not used" 13 "Not used" 14 "Not used" 15 "Unavailable";
VAL_ 1361 AntiUndertakeDisplayRequest 0 "No Request" 1 "Request";
VAL_ 1361 DMS_CancelReason 0 "No display" 1 "HornPad Detected" 2 "Dust Detected" 3 "Number of People Detected" 4 "Obstacle Detected" 5 "Saturation Detected" 6 "Out of normal face area" 7 "Face Undetected" 8 "Eye Undetected" 9 "Out of range" 10 "EEPROM Failure Detected" 11 "Unexecuted Config Detected" 12 "Temporary Failure Detected" 13 "Permanent Failure Detected" 14 "Not used" 15 "Not used";
VAL_ 1369 NextEvent_DisplayRequest 0 "No display" 1 "Next Event Speed Display" 2 "Next Event Type Display" 3 "Next Event Speed and Type Display";
VAL_ 1369 Contextual_ModeStatus 0 "No Display" 1 "Prompt mode" 2 "Allow up" 3 "Allow down" 4 "Auto mode" 5 "Set speed changed by Auto TSR link" 6 "Set speed changed by Manual TSR link" 7 "Not Used";
VAL_ 1369 NextEvent_Speed 254 "Free Speed symbol";
VAL_ 1369 ELKA_AlertLeftRequest 0 "No Alert" 1 "Oncoming Alert level 1" 2 "Oncoming Alert level 2" 3 "Overtaking Alert level 1" 4 "Overtaking Alert level 2" 5 "Roadedge Alert level 1" 6 "Roadedge Alert level 2" 7 "Alert reminder";
VAL_ 1369 RoadEvent_Alert 0 "No Request" 1 "Information" 2 "Warning" 3 "Not Used";
VAL_ 1369 NextEvent_Type 0 "No display" 1 "Right curve" 2 "Speed limit" 3 "Road exit right" 4 "Intersection" 5 "Roundabout" 6 "Stop" 7 "Tollbooth" 8 "Yield sign" 9 "Traffic light" 10 "Traffic jam" 11 "Road work" 12 "Left curve" 13 "Multicurve right-left" 14 "Multicurve left-right" 15 "Bump" 16 "T intersection" 17 "Road exit left" 18 "Slippery Road" 19 "End Of Queue" 20 "Stationary Vehicle" 21 "Broken down Vehicle" 22 "Accident Vehicle" 23 "Unknown Obstacle" 24 "Fog" 25 "Heavy Rain" 26 "Traffic light red" 27 "Traffic light green" 28 "Not used" 29 "Not used" 30 "Not used" 31 "Unavailable";
VAL_ 1369 ContextualEvent_Selection 0 "No display" 1 "Proposal for current event" 2 "Validated for current event" 3 "Proposal for next event" 4 "Validated for next event" 5 "Proposal up for current event" 6 "Proposal down for current event" 7 "Not Used";
VAL_ 1369 ELKA_AlertRightRequest 0 "No Alert" 1 "Oncoming Alert level 1" 2 "Oncoming Alert level 2" 3 "Overtaking Alert level 1" 4 "Overtaking Alert level 2" 5 "Roadedge Alert level 1" 6 "Roadedge Alert level 2" 7 "Alert reminder";
VAL_ 1369 EgoCarCenteringPosition 0 "Not Operative" 1 "Operative Left" 2 "Operative Center" 3 "Operative Right";
VAL_ 1369 SET_ADL3_State 0 "Invalid" 1 "OFF" 2 "ON" 3 "Not used";
VAL_ 1371 HUD_CAN_CorruptionDetection 0 "Not Ready" 1 "No Failure" 2 "Temporary Failure" 3 "Permanent Failure";
VAL_ 1380 MeterLanguageStatus 0 "Unavailable value" 1 "Language 1 à 253" 255 "Not used";
VAL_ 1381 BSWrad_StatusDisplay_v2 0 "No display" 1 "Not operational" 2 "Operational" 3 "Temporary failure" 4 "Permanent failure" 5 "Not Used" 6 "Not Used" 7 "Not Used";
VAL_ 1384 CurrentSpecificUserState 0 "No specific mode" 1 "Valet mode" 2 "Beginner mode" 3 "Not used";
VAL_ 1388 HUD_Status 0 "Not ready" 1 "Available" 2 "Not available" 3 "Failure";
VAL_ 1392 HUD_ADASactivationRequest2 0 "No request" 1 "Activation request" 2 "De-activation request" 3 "Reset request";
VAL_ 1392 HUD_TurnByTurnActivationRequest2 0 "No request" 1 "Activation request" 2 "De-activation request" 3 "Reset request";
VAL_ 1392 HUD_TSRactivationRequest2 0 "No request" 1 "Activation request" 2 "De-activation request" 3 "Reset request";
VAL_ 1402 CASP_DisplayRequest 0 "No request" 1 "Advice" 2 "Reminder" 3 "Reserved";
VAL_ 1402 LDW_LaneDisplay 0 "No display" 1 "Right lane monitoring" 2 "Left lane monitoring" 3 "Right and left lane monitoring";
VAL_ 1402 ProPILOTtransitionRequest 0 "No request" 1 "Request";
VAL_ 1402 LKA_StatusDisplay_v2 0 "No display" 1 "Not operational" 2 "Operational" 3 "Temporary failure" 4 "Permanent failure" 5 "OFF Value" 6 "Not Used" 7 "Not Used";
VAL_ 1402 LDW_StatusDisplay_v2 0 "No display" 1 "Not operational" 2 "Operational" 3 "Temporary failure" 4 "Permanent failure" 5 "OFF Value" 6 "Not Used" 7 "Not Used";
VAL_ 1402 LCA_StatusDisplay_v2 0 "No display" 1 "Not operational" 2 "Operational" 3 "Temporary failure" 4 "Permanent failure" 5 "MRM active" 6 "Not Used" 7 "Not Used";
VAL_ 1414 BrakeMapChangeRequest 0 "Not Used" 1 "No Request" 2 "Request" 3 "Not used" 4 "Not used" 5 "Not used" 6 "Not used" 7 "Unavailable";
VAL_ 1444 HUD_EffectiveDeployment 0 "HUD not deployed" 1 "HUD deployed";
VAL_ 1444 HUD_TSRactivationState 0 "Unavailable" 1 "Activated" 2 "De-activated" 3 "Not used";
VAL_ 1444 HUD_PositionState 0 "Step 1" 1 "Step 2" 2 "Step 3" 3 "Step 4" 4 "Step 5" 5 "Step 6" 6 "Step 7" 7 "Step 8" 8 "Step 9" 9 "Step 10" 10 "Step 11" 11 "Step 12" 12 "Step 13" 13 "Step 14" 14 "Step 15" 15 "Step 16" 16 "Step 17" 17 "Step 18" 18 "Step 19" 19 "Step 20" 20 "Step 21" 21 "Not used" 22 "Not used" 23 "Not used" 24 "Not used" 25 "Not used" 26 "Not used" 27 "Not used" 28 "Not used" 29 "Not used" 30 "Not used" 31 "Not used";
VAL_ 1444 HUD_ActivationState 0 "Unavailable" 1 "HUD activated" 2 "HUD de-activated" 3 "Not used";
VAL_ 1444 HUD_ADASactivationState 0 "Unavailable" 1 "Activated" 2 "De-activated" 3 "Not used";
VAL_ 1444 HUD_TurnByTurnActivationState 0 "Unavailable" 1 "Activated" 2 "De-activated" 3 "Not used";
VAL_ 1444 HUD_ITactivationState 0 "Unavailable" 1 "Activated" 2 "De-activated" 3 "Not used";
VAL_ 1444 HUD_DayLuminosityState 0 "Step 1" 1 "Step 2" 2 "Step 3" 3 "Step 4" 4 "Step 5" 5 "Step 6" 6 "Step 7" 7 "Step 8" 8 "Step 9" 9 "Step 10" 10 "Step 11" 11 "Step 12" 12 "Step 13" 13 "Step 14" 14 "Step 15" 15 "Step 16" 16 "Step 17" 17 "Step 18" 18 "Step 19" 19 "Step 20" 20 "Step 21" 21 "Not used" 22 "Not used" 23 "Not used" 24 "Not used" 25 "Not used" 26 "Not used" 27 "Not used" 28 "Not used" 29 "Not used" 30 "Not used" 31 "Not used";
VAL_ 1444 HUD_TelSMSactivationState 0 "Activated" 1 "No activated";
VAL_ 1444 HUD_NightLuminosityState 0 "Step 1" 1 "Step 2" 2 "Step 3" 3 "Step 4" 4 "Step 5" 5 "Step 6" 6 "Step 7" 7 "Step 8" 8 "Step 9" 9 "Step 10" 10 "Step 11" 11 "Step 12" 12 "Step 13" 13 "Step 14" 14 "Step 15" 15 "Step 16" 16 "Step 17" 17 "Step 18" 18 "Step 19" 19 "Step 20" 20 "Step 21" 21 "Not used" 22 "Not used" 23 "Not used" 24 "Not used" 25 "Not used" 26 "Not used" 27 "Not used" 28 "Not used" 29 "Not used" 30 "Not used" 31 "Not used";
VAL_ 1488 LCA_SteeringWheelTakeOverAlert 0 "No alert" 1 "Alert level 1" 2 "Alert level 2" 3 "Alert level 3" 4 "Alert level 4" 5 "Alert level 5" 6 "Alert level 6" 7 "Alert level 7";
VAL_ 1488 DetectedTargetDisplayRequest 0 "No detected target display requested" 1 "Detected FAR target display requested" 2 "Detected NEAR target display requested" 3 "Detected CLOSE1 target display requested" 4 "Detected CLOSE2 target display requested" 5 "Detected CLOSE3 target display requested" 6 "Not Used" 7 "Not Used";
VAL_ 1488 DW_StatusDisplay 0 "No display" 1 "Not operational" 2 "Operational" 3 "Not used";
VAL_ 1488 DW_FollowUpTimeAlert 0 "No alert" 1 "Alert";
VAL_ 1488 HUD_AD2EnableState 0 "AD2 Not Functional" 1 "AD2 Functional" 2 "SALC Functional" 3 "Unavailable";
VAL_ 1488 ACC_StatusDisplay_v2 0 "No display request" 1 "ACC waiting" 2 "ACC suspended" 3 "ACC activated" 4 "Temporary failure" 5 "Permanent failure" 6 "ACC override" 7 "Not Used";
VAL_ 1490 HUD_IVI_Status 0 "Not Available" 1 "Available_HUD with back light ON" 2 "Available_HUD with back light OFF" 3 "not available because of AD function";
VAL_ 1490 HUD_RotationPositionState 0 "Step 1" 1 "Step 2" 2 "Step 3" 3 "Step 4" 4 "Step 5" 5 "Step 6" 6 "Step 7" 7 "Step 8" 8 "Step 9" 9 "Step 10" 10 "Step 11" 11 "Step 12" 12 "Step 13" 13 "Step 14" 14 "Step 15" 15 "Step 16" 16 "Step 17" 17 "Step 18" 18 "Step 19" 19 "Step 20" 20 "Step 21" 21 "Not used" 22 "Not used" 23 "Not used" 24 "Not used" 25 "Not used" 26 "Not used" 27 "Not used" 28 "Not used" 29 "Not used" 30 "Not used" 31 "Not used";
VAL_ 1490 HUD_SonaractivationState 0 "Activated" 1 "De-activated" 2 "Not Used" 3 "Unavailable";
VAL_ 1490 HUD_FOTA_status 0 "Idle" 1 "Installation in progress" 2 "Copying in progress" 3 "Vehicle Condition check in progress" 4 "Ready for activation" 5 "Switch in progress" 6 "Reboot in progress" 7 "Component version check in progress" 8 "Configuration install in progress" 9 "Activation complete" 10 "Cancel in progress" 11 "Error detected" 12 "Update Error detected" 13 "Rollback in progress" 14 "Rollback complete" 15 "Ready for Slave Distribution" 16 "Slave Distribution in progress" 17 "Slave Integrity check in progress" 18 "Slave Distribution complete" 19 "Slave Installation in progress" 20 "Slave Copying in progress" 21 "Slave Installation complete" 22 "Not used" 23 "Not used" 24 "Not used" 25 "Not used" 26 "Not used" 27 "Not used" 28 "Not used" 29 "Not used" 30 "Not used" 31 "invalid";
VAL_ 1490 HUD_SSAActivationState 0 "Activated" 1 "De-activated" 2 "Not Used" 3 "Unavailable";
VAL_ 1490 HUD_ShiftActivationState 0 "Activated" 1 "De-activated" 2 "Not Used" 3 "Unavailable";
VAL_ 1498 AD_DistanceDuration 0 "No Display" 1023 "Unavailable Value";
VAL_ 1498 AD_TimeDuration 0 "No Display";
VAL_ 1501 TSR_OSP_SubsignAdditional_Zone3 0 "No Display" 1 "TIME area" 2 "SCHOOL area" 3 "Not Used";
VAL_ 1501 TSR_OSP_SubsignAdditional_Zone2 0 "No Display" 1 "TIME area" 2 "SCHOOL area" 3 "Not Used";
VAL_ 1501 TSR_OSP_SubsignAdditional_Zone1 0 "No Display" 1 "TIME area" 2 "SCHOOL area" 3 "Not Used";
VAL_ 1506 HDC_Activation 0 "HDC available" 1 "HDC disable" 2 "Not used" 3 "Unavailable";
VAL_ 1519 UserSettingCopySource 0 "Not copy" 1 "Guest" 2 "User1" 3 "User2" 4 "User3" 5 "User4" 6 "User5" 7 "Not used";
VAL_ 1519 UserSettingCopyTarget 0 "Not copy" 1 "Guest" 2 "User1" 3 "User2" 4 "User3" 5 "User4" 6 "User5" 7 "Not used";
VAL_ 1519 User5_RegistrationState 0 "Not Registered" 1 "Registered";
VAL_ 1519 User4_RegistrationState 0 "Not Registered" 1 "Registered";
VAL_ 1519 KeyLinkInitializationState 0 "Initialization in progress" 1 "Initialization completed";
VAL_ 1519 KeyLinkActivationState 0 "Activate" 1 "Deactivate";
VAL_ 1519 User3_RegistrationState 0 "Not Registered" 1 "Registered";
VAL_ 1519 User2_RegistrationState 0 "Not Registered" 1 "Registered";
VAL_ 1519 User1_RegistrationState 0 "Not Registered" 1 "Registered";
VAL_ 1519 UserSettingCopyRequest 0 "No request" 1 "Request";
VAL_ 1519 CurrentUserState_v2 0 "Guest" 1 "User 1" 2 "User 2" 3 "User 3" 4 "User 4" 5 "User 5" 6 "Not used" 7 "Unavailable";
VAL_ 1529 HUD_ActivationRequest2 0 "No request" 1 "Deployment Activation request" 2 "Deployment Deactivation request" 3 "Reset request";
VAL_ 1529 HUD_PositionRequest2 0 "No request" 1 "Step 1" 2 "Step 2" 3 "Step 3" 4 "Step 4" 5 "Step 5" 6 "Step 6" 7 "Step 7" 8 "Step 8" 9 "Step 9" 10 "Step 10" 11 "Step 11" 12 "Step 12" 13 "Step 13" 14 "Step 14" 15 "Step 15" 16 "Step 16" 17 "Step 17" 18 "Step 18" 19 "Step 19" 20 "Step 20" 21 "Step 21" 22 "Not used" 23 "Not used" 24 "Not used" 25 "Not used" 26 "Not used" 27 "Not used" 28 "Not used" 29 "Not used" 30 "Not used" 31 "Reset request";
VAL_ 1529 HUD_NightLuminosityRequest2 0 "No Request" 1 "Step 1" 2 "Step 2" 3 "Step 3" 4 "Step 4" 5 "Step 5" 6 "Step 6" 7 "Step 7" 8 "Step 8" 9 "Step 9" 10 "Step 10" 11 "Step 11" 12 "Step 12" 13 "Step 13" 14 "Step 14" 15 "Step 15" 16 "Step 16" 17 "Step 17" 18 "Step 18" 19 "Step 19" 20 "Step 20" 21 "Step 21" 22 "Not used" 23 "Not used" 24 "Not used" 25 "Not used" 26 "Not used" 27 "Not used" 28 "Not used" 29 "Not used" 30 "Not used" 31 "Reset request";
VAL_ 1530 HUD_TurnByTurnActivationRequest 0 "No request" 1 "Activation request" 2 "De-activation request" 3 "Reset request";
VAL_ 1530 HUD_ADASactivationRequest 0 "No request" 1 "Activation request" 2 "De-activation request" 3 "Reset request";
VAL_ 1530 HUD_TSRactivationRequest 0 "No request" 1 "Activation request" 2 "De-activation request" 3 "Reset request";
VAL_ 1530 HUD_ITactivationRequest 0 "No request" 1 "Activation request" 2 "De-activation request" 3 "Reset request";
VAL_ 1530 HUD_DayLuminosityRequest 0 "No Request" 1 "Step 1" 2 "Step 2" 3 "Step 3" 4 "Step 4" 5 "Step 5" 6 "Step 6" 7 "Step 7" 8 "Step 8" 9 "Step 9" 10 "Step 10" 11 "Step 11" 12 "Step 12" 13 "Step 13" 14 "Step 14" 15 "Step 15" 16 "Step 16" 17 "Step 17" 18 "Step 18" 19 "Step 19" 20 "Step 20" 21 "Step 21" 22 "Not used" 23 "Not used" 24 "Not used" 25 "Not used" 26 "Not used" 27 "Not used" 28 "Not used" 29 "Not used" 30 "Not used" 31 "Reset request";
VAL_ 1530 HUD_NightLuminosityRequest 0 "No Request" 1 "Step 1" 2 "Step 2" 3 "Step 3" 4 "Step 4" 5 "Step 5" 6 "Step 6" 7 "Step 7" 8 "Step 8" 9 "Step 9" 10 "Step 10" 11 "Step 11" 12 "Step 12" 13 "Step 13" 14 "Step 14" 15 "Step 15" 16 "Step 16" 17 "Step 17" 18 "Step 18" 19 "Step 19" 20 "Step 20" 21 "Step 21" 22 "Not used" 23 "Not used" 24 "Not used" 25 "Not used" 26 "Not used" 27 "Not used" 28 "Not used" 29 "Not used" 30 "Not used" 31 "Reset request";
VAL_ 1530 VDCactivationRequest 0 "No request" 1 "VDC function activation" 2 "VDC function deactivation" 3 "Reset request";
VAL_ 1537 NoEntry_AlertDisplay 0 "No Alert" 1 "Alert";
VAL_ 1537 ADAS_ModeDisplay 0 "Cruise Control mode" 1 "Adaptive Cruise Control mode" 2 "TJP mode" 3 "Unavailable";
VAL_ 1537 NoEntry_Alert 0 "No Alert" 1 "Alert";
VAL_ 1537 ACC_TargetDistanceAlert 0 "No ACC warning" 1 "ACC approach warning" 2 "ACC collision warning" 3 "ACC cancel warning";
VAL_ 1537 ACC_DistanceOverrideDisplay 0 "No override" 1 "Override";
VAL_ 1537 ACC_SpeedOverrideDisplay 0 "No override" 1 "Override";
VAL_ 1537 ACC_TargetDistanceDisplay 0 "No detected target" 1 "Long detected distance" 2 "Middle detected distance" 3 "Short detected distance" 4 "Reglementary detected distance" 5 "Reserved" 6 "Reserved" 7 "Reserved";
VAL_ 1537 ACC_DistanceSettingDisplay 0 "No display" 1 "Short distance" 2 "Middle distance" 3 "Long distance" 4 "Reglementary detected distance" 5 "Very long distance" 6 "Reserved" 7 "Reserved";
VAL_ 1537 LCA_FailureDisplay 0 "No display" 1 "Temporary failure display" 2 "Permanent failure display" 3 "Not used";
VAL_ 1537 LCA_OverrideDisplay 0 "No override" 1 "Override";
VAL_ 1537 LCA_SteeringWheelDisplay 0 "Not active - Cancel" 1 "Not active - Temporary Cancel" 2 "Active" 3 "Not used";
VAL_ 1537 LDP_StatusDisplay 0 "No display" 1 "Not operational" 2 "Operational" 3 "Not used";
VAL_ 1537 LDP_LaneDisplay 0 "No display" 1 "Right lane monitoring" 2 "Left lane monitoring" 3 "Right and left lane monitoring";
VAL_ 1537 LDP_AlertStatus 0 "No alert" 1 "Right alert" 2 "Left alert" 3 "Not used";
VAL_ 1537 DriverGuideDisplay 0 "No display" 1 "Text 1 during system off status, request for guidance to display" 2 "Text 2 during activate, during system standby, request for guidance to display" 3 "Text 3 during active, request for guidance to display" 4 "Text 4 during standstill stop, request for guidance to display" 5 "Text 5 Request for guidance to change menu" 6 "Text 6 during autorestart, request for warning to display" 7 "Text7 Limitation of ACC set speed to EV max speed";
VAL_ 1538 LKA_OvertimeAlert 0 "No Alert" 1 "Alert";
VAL_ 1538 LDW_AlertStatus 0 "No alert" 1 "Right alert" 2 "Left alert" 3 "Not used";
VAL_ 1538 EAP_AlertDisplay 0 "No display" 1 "Alert display";
VAL_ 1538 LCA_LineCrossingAlert 0 "No alert" 1 "Right alert" 2 "Left alert" 3 "RIght and left alert";
VAL_ 1563 IUPR_EvapDenom 0 "no increase denominator" 1 "increase denominator" 2 "freeze denominator" 3 "Not used";
VAL_ 1563 IUPR_ColdStartDenom 0 "no increase denominator" 1 "increase denominator" 2 "freeze denominator" 3 "Not used";
VAL_ 1563 IUPR_GeneralDenom 0 "no increase denominator" 1 "increase denominator" 2 "freeze denominator" 3 "Not used";
VAL_ 1563 IgnCycleCount_v2 0 "No Request" 1 "Ignition Cycle count request";
VAL_ 1563 DriveCycle 0 "No Request" 1 "General Denominator Count Request";
VAL_ 1595 HUD_RotationPositionRequest2 0 "No Request" 1 "step 1" 2 "step 2" 3 "step 3" 4 "step 4" 5 "step 5" 6 "step 6" 7 "step 7" 8 "step 8" 9 "step 9" 10 "step 10" 11 "step 11" 12 "step 12" 13 "step 13" 14 "step 14" 15 "step 15" 16 "step 16" 17 "step 17" 18 "step 18" 19 "step 19" 20 "step 20" 21 "step 21" 22 "Reset Request" 23 "Not Used" 24 "Not Used" 25 "Not Used" 26 "Not Used" 27 "Not Used" 28 "Not Used" 29 "Not Used" 30 "Not Used" 31 "Not Used";
VAL_ 1596 NextTurnProximityDetected 0 "No requested" 1 "Navigation picture requested";
VAL_ 1596 TCS_DeactivationRequest2 0 "No request" 1 "TCS deactivation request" 2 "TCS activation request" 3 "Not used";
VAL_ 1596 HDC_ActivationRequest2 0 "HDC not requested" 1 "HDC requested" 2 "Reset requested" 3 "Unavailable";
VAL_ 1614 HUD_TelSMSactivationRequest2 0 "No Request" 1 "Activation request" 2 "De-activation request" 3 "Reset request";
VAL_ 1614 HUD_ITactivationRequest2 0 "No Request" 1 "Activation request" 2 "De-activation request" 3 "Reset request";
VAL_ 1637 DriveModeState 0 "Mode 0=NORMAL/STANDARD/AUTO" 1 "Mode 1=ECO" 2 "Mode 2=SPORT/TARMAC" 3 "Mode 3=SPORT+/POWER" 4 "Mode 4=COMFORT" 5 "Mode 5=PERSONAL" 6 "Mode 6=SNOW" 7 "Mode 7" 8 "Mode 8=OFF-ROAD/GRAVEL" 9 "Mode 9=MUD/RUT" 10 "Mode 10=SAND" 11 "Mode 11=TOW" 12 "Mode 12=ALL ROAD/ROCK" 13 "Mode 13=EXTREM" 14 "Mode 14=PERFO" 15 "Mode 15=VITAMIN" 16 "Mode 16=RACE" 17 "Mode 17" 18 "Mode 18" 19 "Mode 19" 20 "Mode 20" 21 "Mode 21" 22 "Mode 22" 23 "Mode 23" 24 "Mode 24" 25 "Mode 25" 26 "Mode 26" 27 "Mode 27" 28 "Mode 28" 29 "Mode 29" 30 "Mode 30" 31 "Unavailable";
VAL_ 1645 AEB_CyclistAlertRequest2 0 "No AEB cyclist alert" 1 "AEB cyclist alert";
VAL_ 1645 AEB_PedestrianAlertRequest2 0 "No AEB PEDESTRIAN alert" 1 "AEB PEDESTRIAN alert";
VAL_ 1645 AEB_VehicleAlertRequest2 0 "No AEB vehicle alert" 1 "AEB vehicle Approach alert" 2 "AEB vehicle Collision alert" 3 "AEB vehicle Alert reminder";
VAL_ 1645 AEB_JuncAssistAlertRight 0 "No alert" 1 "Junction Assist Information" 2 "Junction Assist Alert" 3 "Not used";
VAL_ 1645 AEB_JuncAssistAlertLeft 0 "No alert" 1 "Junction Assist Information" 2 "Junction Assist Alert" 3 "Not used";
VAL_ 1659 UserIdentification_IKeyLink 0 "No request" 1 "Key No. 1" 2 "Key No. 2" 3 "Key No. 3" 4 "Key No. 4" 5 "Not used" 6 "Not used" 7 "Not used";
VAL_ 1720 HUD_TelSMSactivationRequest 0 "No request" 1 "Activation request" 2 "Deactivation request" 3 "Reset request";
VAL_ 1738 HUD_UpDownRequest 0 "No request" 1 "Up command requested" 2 "Down command requested" 3 "Reset request";
VAL_ 1763 HUD_RotationPositionRequest 0 "No request" 1 "Step 1" 2 "Step 2" 3 "Step 3" 4 "Step 4" 5 "Step 5" 6 "Step 6" 7 "Step 7" 8 "Step 8" 9 "Step 9" 10 "Step 10" 11 "Step 11" 12 "Step 12" 13 "Step 13" 14 "Step 14" 15 "Step 15" 16 "Step 16" 17 "Step 17" 18 "Step 18" 19 "Step 19" 20 "Step 20" 21 "Step 21" 22 "Not used" 23 "Not used" 24 "Not used" 25 "Not used" 26 "Not used" 27 "Not used" 28 "Not used" 29 "Not used" 30 "Not used" 31 "Reset Request";
VAL_ 1765 SWA_Config 0 "Table Value26887";
VAL_ 1772 HUD_SSAActivationRequest 0 "No Request" 1 "Activation request" 2 "De-activation request" 3 "Reset request";
VAL_ 1772 HUD_SonarActivationRequest 0 "No Request" 1 "Activation request" 2 "De-activation request" 3 "Reset request";
VAL_ 1772 HUD_ShiftActivationRequest 0 "No Request" 1 "Activation request" 2 "De-activation request" 3 "Reset request";
VAL_ 2563507968 SIGMA_CDM 0 "Table Value16461";
VAL_ 2563507968 SIGMA_DTCCDM 0 "Table Value26862";
VAL_ 2563508007 SIGMA_eHBox 0 "Table Value430561";
VAL_ 2563508007 SIGMA_DTCeHBox 0 "Table Value430559";
VAL_ 2563508009 SIGMA_PSD_R 0 "Table Value153060";
VAL_ 2563508009 SIGMA_DTCPSD_R 0 "Table Value153056";
VAL_ 2563508019 SIGMA_PBD 0 "Table Value16399";
VAL_ 2563508019 SIGMA_DTCPBD 0 "Table Value26865";
VAL_ 2563508021 SIGMA_RADAR 0 "Table Value16466";
VAL_ 2563508021 SIGMA_DTCRADAR 0 "Table Value26884";
VAL_ 2563508022 SIGMA_PSCU 0 "Table Value16465";
VAL_ 2563508022 SIGMA_DTCPSCU 0 "Table Value26866";
VAL_ 2563508030 SIGMA_SRad_RL 0 "Table Value16470";
VAL_ 2563508030 SIGMA_DTCSRad_RL 0 "Table Value26868";
VAL_ 2563508035 SIGMA_eRDC_L 0 "Table Value252236";
VAL_ 2563508035 SIGMA_DTCeRDC_L 0 "Table Value252232";
VAL_ 2563508037 SIGMA_eRDC_R 0 "Table Value252238";
VAL_ 2563508037 SIGMA_DTCeRDC_R 0 "Table Value252233";
VAL_ 2563508042 SIGMA_ANC 0 "Table Value16458";
VAL_ 2563508042 SIGMA_DTCANC 0 "Table Value26859";
VAL_ 2563508064 SIGMA_VDC 0 "Table Value16380";
VAL_ 2563508064 SIGMA_DTCVDC 0 "Table Value26886";
VAL_ 2563508066 SIGMA_EPS 0 "Table Value16377";
VAL_ 2563508066 SIGMA_DTCEPS 0 "Table Value26879";
VAL_ 2563508067 SIGMA_METER 0 "Table Value16379";
VAL_ 2563508067 SIGMA_DTCMETER 0 "Table Value26883";
VAL_ 2563508068 SIGMA_HVAC 0 "Table Value28686";
VAL_ 2563508068 SIGMA_DTCHVAC 0 "Table Value28682";
VAL_ 2563508069 SIGMA_BCM 0 "Table Value16381";
VAL_ 2563508069 SIGMA_DTCBCM 0 "Table Value26877";
VAL_ 2563508071 SIGMA_IVI 0 "Table Value16383";
VAL_ 2563508071 SIGMA_DTCIVI 0 "Table Value26882";
VAL_ 2563508072 SIGMA_4WD 0 "Table Value28679";
VAL_ 2563508072 SIGMA_DTC4WD 0 "Table Value28678";
VAL_ 2563508077 SIGMA_USM 0 "Table Value16384";
VAL_ 2563508077 SIGMA_DTCUSM 0 "Table Value26885";
VAL_ 2563508078 SIGMA_SONAR 0 "Table Value28703";
VAL_ 2563508078 SIGMA_DTCSONAR 0 "Table Value28702";
VAL_ 2563508079 SIGMA_DSMU 0 "Table Value16462";
VAL_ 2563508079 SIGMA_DTCDSMU 0 "Table Value26863";
VAL_ 2563508082 SIGMA_ACU 0 "Table Value16374";
VAL_ 2563508082 SIGMA_DTCACU 0 "Table Value26874";
VAL_ 2563508089 SIGMA_PSD_L 0 "Table Value153059";
VAL_ 2563508089 SIGMA_DTCPSD_L 0 "Table Value153054";
VAL_ 2563508093 SIGMA_ADAS 0 "Table Value16457";
VAL_ 2563508093 SIGMA_DTCADAS 0 "Table Value26875";
VAL_ 2563508099 SIGMA_A_IVC 0 "Table Value16456";
VAL_ 2563508099 SIGMA_DTCA_IVC 0 "Table Value26858";
VAL_ 2563508108 SIGMA_INV_ME 0 "Table Value27356";
VAL_ 2563508108 SIGMA_DTCINV_ME 0 "Table Value27351";
VAL_ 2563508115 SIGMA_OBC_AC 0 "Table Value28687";
VAL_ 2563508115 SIGMA_DTCOBC_AC 0 "Table Value28683";
VAL_ 2563508122 SIGMA_HEVC 0 "Table Value27338";
VAL_ 2563508122 SIGMA_DTCHEVC 0 "Table Value27347";
VAL_ 2563508130 SIGMA_AUDIOamp 0 "Table Value16459";
VAL_ 2563508130 SIGMA_DTCAUDIOamp 0 "Table Value26860";
VAL_ 2563508133 SIGMA_HNS 0 "Table Value27353";
VAL_ 2563508133 SIGMA_DTCHNS 0 "Table Value27348";
VAL_ 2563508139 SIGMA_VKM 0 "Table Value252239";
VAL_ 2563508139 SIGMA_DTCVKM 0 "Table Value252234";
VAL_ 2563508153 SIGMA_HFM 0 "Table Value16382";
VAL_ 2563508153 SIGMA_DTCHFM 0 "Table Value26881";
VAL_ 2563508154 SIGMA_AVM 0 "Table Value27338";
VAL_ 2563508154 SIGMA_DTCAVM 0 "Table Value27343";
VAL_ 2563508157 SIGMA_SCU 0 "Table Value28688";
VAL_ 2563508157 SIGMA_DTCSCU 0 "Table Value28684";
VAL_ 2563508164 SIGMA_eShifter 0 "Table Value153058";
VAL_ 2563508164 SIGMA_DTCeShifter 0 "Table Value153055";
VAL_ 2563508181 SIGMA_SRad_RR 0 "Table Value16471";
VAL_ 2563508181 SIGMA_DTCSRad_RR 0 "Table Value26871";
VAL_ 2563508189 SIGMA_FrCamera 0 "Table Value16378";
VAL_ 2563508189 SIGMA_DTCFrCamera 0 "Table Value26880";
VAL_ 2563508200 SIGMA_ECM 0 "Table Value16376";
VAL_ 2563508200 SIGMA_DTCECM 0 "Table Value26878";
VAL_ 2563508201 SIGMA_ATCU 0 "Table Value16375";
VAL_ 2563508201 SIGMA_DTCATCU 0 "Table Value26876";
VAL_ 2563508205 SIGMA_BMS_HV 0 "Table Value27340";
VAL_ 2563508205 SIGMA_DTCBMS_HV 0 "Table Value27344";
VAL_ 2563508207 SIGMA_INV_HSG 0 "Table Value27355";
VAL_ 2563508207 SIGMA_DTCINV_HSG 0 "Table Value27350";
VAL_ 2563567883 SIGMA_BMS_12V 0 "Table Value16460";
VAL_ 2563567883 SIGMA_DTCBMS_12V 0 "Table Value26861";
VAL_ 2563567951 SIGMA_EPS_sub 0 "Table Value28685";
VAL_ 2563567951 SIGMA_DTCEPS_sub 0 "Table Value28681";
VAL_ 2563567958 SIGMA_eShiftAct 0 "Table Value153057";
VAL_ 2563567958 SIGMA_DTCeShiftAct 0 "Table Value153053";
VAL_ 2563567968 SIGMA_HUD 0 "Table Value27354";
VAL_ 2563567968 SIGMA_DTCHUD 0 "Table Value27349";
VAL_ 2563568024 SIGMA_HPCU 0 "Table Value55692";
VAL_ 2563568024 SIGMA_DTCHPCU 0 "Table Value55693";
VAL_ 2563568093 SIGMA_DCDC_HV 0 "Table Value28677";
VAL_ 2563568093 SIGMA_DTCDCDC_HV 0 "Table Value28680";
VAL_ 2563568098 SIGMA_EBA 0 "Table Value16463";
VAL_ 2563568098 SIGMA_DTCEBA 0 "Table Value26864";
VAL_ 2563568101 SIGMA_INV_RE 0 "Table Value27357";
VAL_ 2563568101 SIGMA_DTCINV_RE 0 "Table Value27352";
VAL_ 2563568130 SIGMA_AirSUSP 0 "Table Value359670";
VAL_ 2563568130 SIGMA_DTCAirSUSP 0 "Table Value359671";
VAL_ 2563568148 SIGMA_BSG 0 "Table Value27341";
VAL_ 2563568148 SIGMA_DTCBSG 0 "Table Value27345";
VAL_ 2563568163 SIGMA_SRad_FL 0 "Table Value16468";
VAL_ 2563568163 SIGMA_DTCSRad_FL 0 "Table Value26869";
VAL_ 2563568164 SIGMA_SRad_FR 0 "Table Value16469";
VAL_ 2563568164 SIGMA_DTCSRad_FR 0 "Table Value26870";
VAL_ 2563568201 SIGMA_STBW 0 "Table Value161590";
VAL_ 2563568201 SIGMA_DTCSTBW 0 "Table Value161588";
VAL_ 2563568233 SIGMA_DMC 0 "Table Value27342";
VAL_ 2563568233 SIGMA_DTCDMC 0 "Table Value27346";
VAL_ 2563568267 SIGMA_RSCU3R 0 "Table Value407697";
VAL_ 2563568267 SIGMA_DTCRSCU3R 0 "Table Value407696";
VAL_ 2563568288 SIGMA_BLM_RPK 0 "Table Value55679";
VAL_ 2563568288 SIGMA_DTCBLM_RPK 0 "Table Value55690";
VAL_ 2563568290 SIGMA_SCCM 0 "Table Value16467";
VAL_ 2563568290 SIGMA_DTCSCCM 0 "Table Value26867";
VAL_ 2563568300 SIGMA_RSCU2R 0 "Table Value359675";
VAL_ 2563568300 SIGMA_DTCRSCU2R 0 "Table Value359672";
VAL_ 2609102859 CDM_WakeUp_Signal 0 "Table Value16476";
VAL_ 2615042289 FTOOLS_CGWtoHUD 0 "Table Value30451";
VAL_ 2615079264 FTOOLS_HUDtoCGW 0 "Table Value30465";
